AUTOSAR XML (schema 4-2-2)
package /STELLANTIS/EPT/COMSWCs
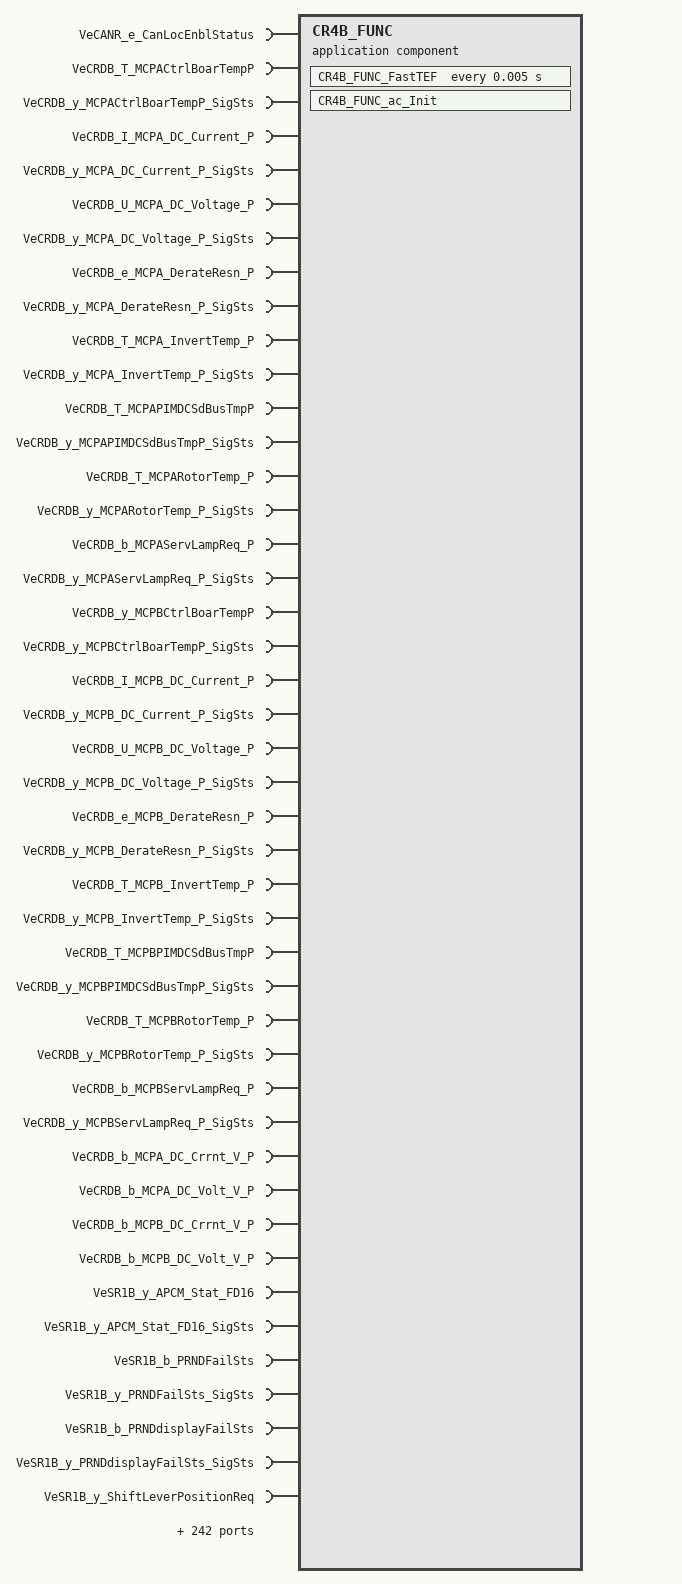
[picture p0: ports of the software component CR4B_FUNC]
  application sw component type CR4B_FUNC
    286 x require port:
      VeCANR_e_CanLocEnblStatus: nonqueued-receiver-com-spec{data-element=VeCANR_e_CanLocEnblStatus, init-value=0}, required-interface=VeCANR_e_CanLocEnblStatus
      VeCRDB_T_MCPACtrlBoarTempP: variation-point={short-label=vpVeCRDB_T_MCPACtrlBoarTempP, sw-syscond=1}, nonqueued-receiver-com-spec{data-element=Value, handle-never-received=true, init-value=0}, required-interface=VeCRDB_T_MCPACtrlBoarTempP
      VeCRDB_y_MCPACtrlBoarTempP_SigSts: variation-point={short-label=vpVeCRDB_y_MCPACtrlBoarTempP_SigSts, sw-syscond=1}, nonqueued-receiver-com-spec{data-element=Value, init-value=0}, required-interface=VeCRDB_y_MCPACtrlBoarTempP_SigSts
      VeCRDB_I_MCPA_DC_Current_P: variation-point={short-label=vpVeCRDB_I_MCPA_DC_Current_P, sw-syscond=1}, nonqueued-receiver-com-spec{data-element=Value, handle-never-received=true, init-value=0}, required-interface=VeCRDB_I_MCPA_DC_Current_P
      VeCRDB_y_MCPA_DC_Current_P_SigSts: variation-point={short-label=vpVeCRDB_y_MCPA_DC_Current_P_SigSts, sw-syscond=1}, nonqueued-receiver-com-spec{data-element=Value, init-value=0}, required-interface=VeCRDB_y_MCPA_DC_Current_P_SigSts
      VeCRDB_U_MCPA_DC_Voltage_P: variation-point={short-label=vpVeCRDB_U_MCPA_DC_Voltage_P, sw-syscond=1}, nonqueued-receiver-com-spec{data-element=Value, handle-never-received=true, init-value=0}, required-interface=VeCRDB_U_MCPA_DC_Voltage_P
      VeCRDB_y_MCPA_DC_Voltage_P_SigSts: variation-point={short-label=vpVeCRDB_y_MCPA_DC_Voltage_P_SigSts, sw-syscond=1}, nonqueued-receiver-com-spec{data-element=Value, init-value=0}, required-interface=VeCRDB_y_MCPA_DC_Voltage_P_SigSts
      VeCRDB_e_MCPA_DerateResn_P: variation-point={short-label=vpVeCRDB_e_MCPA_DerateResn_P, sw-syscond=1}, nonqueued-receiver-com-spec{data-element=Value, handle-never-received=true, init-value=0}, required-interface=VeCRDB_e_MCPA_DerateResn_P
      VeCRDB_y_MCPA_DerateResn_P_SigSts: variation-point={short-label=vpVeCRDB_y_MCPA_DerateResn_P_SigSts, sw-syscond=1}, nonqueued-receiver-com-spec{data-element=Value, init-value=0}, required-interface=VeCRDB_y_MCPA_DerateResn_P_SigSts
      VeCRDB_T_MCPA_InvertTemp_P: variation-point={short-label=vpVeCRDB_T_MCPA_InvertTemp_P, sw-syscond=1}, nonqueued-receiver-com-spec{data-element=Value, handle-never-received=true, init-value=0}, required-interface=VeCRDB_T_MCPA_InvertTemp_P
      VeCRDB_y_MCPA_InvertTemp_P_SigSts: variation-point={short-label=vpVeCRDB_y_MCPA_InvertTemp_P_SigSts, sw-syscond=1}, nonqueued-receiver-com-spec{data-element=Value, init-value=0}, required-interface=VeCRDB_y_MCPA_InvertTemp_P_SigSts
      VeCRDB_T_MCPAPIMDCSdBusTmpP: variation-point={short-label=vpVeCRDB_T_MCPAPIMDCSdBusTmpP, sw-syscond=1}, nonqueued-receiver-com-spec{data-element=Value, handle-never-received=true, init-value=0}, required-interface=VeCRDB_T_MCPAPIMDCSdBusTmpP
      VeCRDB_y_MCPAPIMDCSdBusTmpP_SigSts: variation-point={short-label=vpVeCRDB_y_MCPAPIMDCSdBusTmpP_SigSts, sw-syscond=1}, nonqueued-receiver-com-spec{data-element=Value, init-value=0}, required-interface=VeCRDB_y_MCPAPIMDCSdBusTmpP_SigSts
      VeCRDB_T_MCPARotorTemp_P: variation-point={short-label=vpVeCRDB_T_MCPARotorTemp_P, sw-syscond=1}, nonqueued-receiver-com-spec{data-element=Value, handle-never-received=true, init-value=0}, required-interface=VeCRDB_T_MCPARotorTemp_P
      VeCRDB_y_MCPARotorTemp_P_SigSts: variation-point={short-label=vpVeCRDB_y_MCPARotorTemp_P_SigSts, sw-syscond=1}, nonqueued-receiver-com-spec{data-element=Value, init-value=0}, required-interface=VeCRDB_y_MCPARotorTemp_P_SigSts
      VeCRDB_b_MCPAServLampReq_P: variation-point={short-label=vpVeCRDB_b_MCPAServLampReq_P, sw-syscond=1}, nonqueued-receiver-com-spec{data-element=Value, handle-never-received=true, init-value=0}, required-interface=VeCRDB_b_MCPAServLampReq_P
      VeCRDB_y_MCPAServLampReq_P_SigSts: variation-point={short-label=vpVeCRDB_y_MCPAServLampReq_P_SigSts, sw-syscond=1}, nonqueued-receiver-com-spec{data-element=Value, init-value=0}, required-interface=VeCRDB_y_MCPAServLampReq_P_SigSts
      VeCRDB_y_MCPBCtrlBoarTempP: nonqueued-receiver-com-spec{data-element=Value, handle-never-received=true, init-value=0}, required-interface=VeCRDB_y_MCPBCtrlBoarTempP
      VeCRDB_y_MCPBCtrlBoarTempP_SigSts: nonqueued-receiver-com-spec{data-element=Value, init-value=0}, required-interface=VeCRDB_y_MCPBCtrlBoarTempP_SigSts
      VeCRDB_I_MCPB_DC_Current_P: nonqueued-receiver-com-spec{data-element=Value, handle-never-received=true, init-value=0}, required-interface=VeCRDB_I_MCPB_DC_Current_P
      VeCRDB_y_MCPB_DC_Current_P_SigSts: nonqueued-receiver-com-spec{data-element=Value, init-value=0}, required-interface=VeCRDB_y_MCPB_DC_Current_P_SigSts
      VeCRDB_U_MCPB_DC_Voltage_P: nonqueued-receiver-com-spec{data-element=Value, handle-never-received=true, init-value=0}, required-interface=VeCRDB_U_MCPB_DC_Voltage_P
      VeCRDB_y_MCPB_DC_Voltage_P_SigSts: nonqueued-receiver-com-spec{data-element=Value, init-value=0}, required-interface=VeCRDB_y_MCPB_DC_Voltage_P_SigSts
      VeCRDB_e_MCPB_DerateResn_P: nonqueued-receiver-com-spec{data-element=Value, handle-never-received=true, init-value=0}, required-interface=VeCRDB_e_MCPB_DerateResn_P
      VeCRDB_y_MCPB_DerateResn_P_SigSts: nonqueued-receiver-com-spec{data-element=Value, init-value=0}, required-interface=VeCRDB_y_MCPB_DerateResn_P_SigSts
      VeCRDB_T_MCPB_InvertTemp_P: nonqueued-receiver-com-spec{data-element=Value, handle-never-received=true, init-value=0}, required-interface=VeCRDB_T_MCPB_InvertTemp_P
      VeCRDB_y_MCPB_InvertTemp_P_SigSts: nonqueued-receiver-com-spec{data-element=Value, init-value=0}, required-interface=VeCRDB_y_MCPB_InvertTemp_P_SigSts
      VeCRDB_T_MCPBPIMDCSdBusTmpP: nonqueued-receiver-com-spec{data-element=Value, handle-never-received=true, init-value=0}, required-interface=VeCRDB_T_MCPBPIMDCSdBusTmpP
      VeCRDB_y_MCPBPIMDCSdBusTmpP_SigSts: nonqueued-receiver-com-spec{data-element=Value, init-value=0}, required-interface=VeCRDB_y_MCPBPIMDCSdBusTmpP_SigSts
      VeCRDB_T_MCPBRotorTemp_P: nonqueued-receiver-com-spec{data-element=Value, handle-never-received=true, init-value=0}, required-interface=VeCRDB_T_MCPBRotorTemp_P
      VeCRDB_y_MCPBRotorTemp_P_SigSts: nonqueued-receiver-com-spec{data-element=Value, init-value=0}, required-interface=VeCRDB_y_MCPBRotorTemp_P_SigSts
      VeCRDB_b_MCPBServLampReq_P: nonqueued-receiver-com-spec{data-element=Value, handle-never-received=true, init-value=0}, required-interface=VeCRDB_b_MCPBServLampReq_P
      VeCRDB_y_MCPBServLampReq_P_SigSts: nonqueued-receiver-com-spec{data-element=Value, init-value=0}, required-interface=VeCRDB_y_MCPBServLampReq_P_SigSts
      VeCRDB_b_MCPA_DC_Crrnt_V_P: variation-point={short-label=vpVeCRDB_b_MCPA_DC_Crrnt_V_P, sw-syscond=1}, nonqueued-receiver-com-spec{data-element=Value, init-value=0}, required-interface=VeCRDB_b_MCPA_DC_Crrnt_V_P
      VeCRDB_b_MCPA_DC_Volt_V_P: variation-point={short-label=vpVeCRDB_b_MCPA_DC_Volt_V_P, sw-syscond=1}, nonqueued-receiver-com-spec{data-element=Value, init-value=0}, required-interface=VeCRDB_b_MCPA_DC_Volt_V_P
      VeCRDB_b_MCPB_DC_Crrnt_V_P: nonqueued-receiver-com-spec{data-element=Value, init-value=0}, required-interface=VeCRDB_b_MCPB_DC_Crrnt_V_P
      VeCRDB_b_MCPB_DC_Volt_V_P: nonqueued-receiver-com-spec{data-element=Value, init-value=0}, required-interface=VeCRDB_b_MCPB_DC_Volt_V_P
      VeSR1B_y_APCM_Stat_FD16: nonqueued-receiver-com-spec{data-element=Value, handle-never-received=true, init-value=0}, required-interface=VeSR1B_y_APCM_Stat_FD16
      VeSR1B_y_APCM_Stat_FD16_SigSts: nonqueued-receiver-com-spec{data-element=Value, init-value=0}, required-interface=VeSR1B_y_APCM_Stat_FD16_SigSts
      VeSR1B_b_PRNDFailSts: nonqueued-receiver-com-spec{data-element=Value, handle-never-received=true, init-value=0}, required-interface=VeSR1B_b_PRNDFailSts
      VeSR1B_y_PRNDFailSts_SigSts: nonqueued-receiver-com-spec{data-element=Value, init-value=0}, required-interface=VeSR1B_y_PRNDFailSts_SigSts
      VeSR1B_b_PRNDdisplayFailSts: nonqueued-receiver-com-spec{data-element=Value, handle-never-received=true, init-value=0}, required-interface=VeSR1B_b_PRNDdisplayFailSts
      VeSR1B_y_PRNDdisplayFailSts_SigSts: nonqueued-receiver-com-spec{data-element=Value, init-value=0}, required-interface=VeSR1B_y_PRNDdisplayFailSts_SigSts
      VeSR1B_y_ShiftLeverPositionReq: nonqueued-receiver-com-spec{data-element=Value, handle-never-received=true, init-value=0}, required-interface=VeSR1B_y_ShiftLeverPositionReq
      VeSR1B_y_ShiftLeverPositionReq_SigSts: nonqueued-receiver-com-spec{data-element=Value, init-value=0}, required-interface=VeSR1B_y_ShiftLeverPositionReq_SigSts
      VeCRDB_y_MCPA_6SO_Status_P: variation-point={short-label=vpVeCRDB_y_MCPA_6SO_Status_P, sw-syscond=1}, nonqueued-receiver-com-spec{data-element=Value, handle-never-received=true, init-value=0}, required-interface=VeCRDB_y_MCPA_6SO_Status_P
      VeCRDB_y_MCPA_6SO_Status_P_SigSts: variation-point={short-label=vpVeCRDB_y_MCPA_6SO_Status_P_SigSts, sw-syscond=1}, nonqueued-receiver-com-spec{data-element=Value, init-value=0}, required-interface=VeCRDB_y_MCPA_6SO_Status_P_SigSts
      VeCRDB_y_MCPA_AccelRaw_P: variation-point={short-label=vpVeCRDB_y_MCPA_AccelRaw_P, sw-syscond=1}, nonqueued-receiver-com-spec{data-element=Value, handle-never-received=true, init-value=0}, required-interface=VeCRDB_y_MCPA_AccelRaw_P
      VeCRDB_y_MCPA_AccelRaw_P_SigSts: variation-point={short-label=vpVeCRDB_y_MCPA_AccelRaw_P_SigSts, sw-syscond=1}, nonqueued-receiver-com-spec{data-element=Value, init-value=0}, required-interface=VeCRDB_y_MCPA_AccelRaw_P_SigSts
      VeCRDB_n_MCPA_CpbltySpdDvVolt_P: variation-point={short-label=vpVeCRDB_n_MCPA_CpbltySpdDvVolt_P, sw-syscond=1}, nonqueued-receiver-com-spec{data-element=Value, handle-never-received=true, init-value=0}, required-interface=VeCRDB_n_MCPA_CpbltySpdDvVolt_P
      VeCRDB_y_MCPA_CpbltySpdDvVolt_P_SigSts: variation-point={short-label=vpVeCRDB_y_MCPA_CpbltySpdDvVolt_P_SigSts, sw-syscond=1}, nonqueued-receiver-com-spec{data-element=Value, init-value=0}, required-interface=VeCRDB_y_MCPA_CpbltySpdDvVolt_P_SigSts
      VeCRDB_h_MCPA_DeratingFactor_P: variation-point={short-label=vpVeCRDB_h_MCPA_DeratingFactor_P, sw-syscond=1}, nonqueued-receiver-com-spec{data-element=Value, handle-never-received=true, init-value=0}, required-interface=VeCRDB_h_MCPA_DeratingFactor_P
      VeCRDB_y_MCPA_DeratingFactor_P_SigSts: variation-point={short-label=vpVeCRDB_y_MCPA_DeratingFactor_P_SigSts, sw-syscond=1}, nonqueued-receiver-com-spec{data-element=Value, init-value=0}, required-interface=VeCRDB_y_MCPA_DeratingFactor_P_SigSts
      VeCRDB_y_MCPA_Dschrge_Status_P: variation-point={short-label=vpVeCRDB_y_MCPA_Dschrge_Status_P, sw-syscond=1}, nonqueued-receiver-com-spec{data-element=Value, handle-never-received=true, init-value=0}, required-interface=VeCRDB_y_MCPA_Dschrge_Status_P
      VeCRDB_y_MCPA_Dschrge_Status_P_SigSts: variation-point={short-label=vpVeCRDB_y_MCPA_Dschrge_Status_P_SigSts, sw-syscond=1}, nonqueued-receiver-com-spec{data-element=Value, init-value=0}, required-interface=VeCRDB_y_MCPA_Dschrge_Status_P_SigSts
      VeCRDB_b_MCPA_HV_CnctrOpn_Req_P: variation-point={short-label=vpVeCRDB_b_MCPA_HV_CnctrOpn_Req_P, sw-syscond=1}, nonqueued-receiver-com-spec{data-element=Value, handle-never-received=true, init-value=0}, required-interface=VeCRDB_b_MCPA_HV_CnctrOpn_Req_P
      VeCRDB_y_MCPA_HV_CnctrOpn_Req_P_SigSts: variation-point={short-label=vpVeCRDB_y_MCPA_HV_CnctrOpn_Req_P_SigSts, sw-syscond=1}, nonqueued-receiver-com-spec{data-element=Value, init-value=0}, required-interface=VeCRDB_y_MCPA_HV_CnctrOpn_Req_P_SigSts
      VeCRDB_y_MCPA_InterlockSts_P: variation-point={short-label=vpVeCRDB_y_MCPA_InterlockSts_P, sw-syscond=1}, nonqueued-receiver-com-spec{data-element=Value, handle-never-received=true, init-value=0}, required-interface=VeCRDB_y_MCPA_InterlockSts_P
      VeCRDB_y_MCPA_InterlockSts_P_SigSts: variation-point={short-label=vpVeCRDB_y_MCPA_InterlockSts_P_SigSts, sw-syscond=1}, nonqueued-receiver-com-spec{data-element=Value, init-value=0}, required-interface=VeCRDB_y_MCPA_InterlockSts_P_SigSts
      VeCRDB_y_MCPA_Invrtr_State_P: variation-point={short-label=vpVeCRDB_y_MCPA_Invrtr_State_P, sw-syscond=1}, nonqueued-receiver-com-spec{data-element=Value, handle-never-received=true, init-value=0}, required-interface=VeCRDB_y_MCPA_Invrtr_State_P
      VeCRDB_y_MCPA_Invrtr_State_P_SigSts: variation-point={short-label=vpVeCRDB_y_MCPA_Invrtr_State_P_SigSts, sw-syscond=1}, nonqueued-receiver-com-spec{data-element=Value, init-value=0}, required-interface=VeCRDB_y_MCPA_Invrtr_State_P_SigSts
      VeCRDB_M_MCPA_MaxTorq_P: variation-point={short-label=vpVeCRDB_M_MCPA_MaxTorq_P, sw-syscond=1}, nonqueued-receiver-com-spec{data-element=Value, handle-never-received=true, init-value=0}, required-interface=VeCRDB_M_MCPA_MaxTorq_P
      VeCRDB_y_MCPA_MaxTorq_P_SigSts: variation-point={short-label=vpVeCRDB_y_MCPA_MaxTorq_P_SigSts, sw-syscond=1}, nonqueued-receiver-com-spec{data-element=Value, init-value=0}, required-interface=VeCRDB_y_MCPA_MaxTorq_P_SigSts
      VeCRDB_M_MCPA_MinTorq_P: variation-point={short-label=vpVeCRDB_M_MCPA_MinTorq_P, sw-syscond=1}, nonqueued-receiver-com-spec{data-element=Value, handle-never-received=true, init-value=0}, required-interface=VeCRDB_M_MCPA_MinTorq_P
      VeCRDB_y_MCPA_MinTorq_P_SigSts: variation-point={short-label=vpVeCRDB_y_MCPA_MinTorq_P_SigSts, sw-syscond=1}, nonqueued-receiver-com-spec{data-element=Value, init-value=0}, required-interface=VeCRDB_y_MCPA_MinTorq_P_SigSts
      VeCRDB_M_MCPA_MtrMaxCpbltyTrq_P: variation-point={short-label=vpVeCRDB_M_MCPA_MtrMaxCpbltyTrq_P, sw-syscond=1}, nonqueued-receiver-com-spec{data-element=Value, handle-never-received=true, init-value=0}, required-interface=VeCRDB_M_MCPA_MtrMaxCpbltyTrq_P
      VeCRDB_y_MCPA_MtrMaxCpbltyTrq_P_SigSts: variation-point={short-label=vpVeCRDB_y_MCPA_MtrMaxCpbltyTrq_P_SigSts, sw-syscond=1}, nonqueued-receiver-com-spec{data-element=Value, init-value=0}, required-interface=VeCRDB_y_MCPA_MtrMaxCpbltyTrq_P_SigSts
      VeCRDB_M_MCPA_MtrMinCpbltyTrq_P: variation-point={short-label=vpVeCRDB_M_MCPA_MtrMinCpbltyTrq_P, sw-syscond=1}, nonqueued-receiver-com-spec{data-element=Value, handle-never-received=true, init-value=0}, required-interface=VeCRDB_M_MCPA_MtrMinCpbltyTrq_P
      VeCRDB_y_MCPA_MtrMinCpbltyTrq_P_SigSts: variation-point={short-label=vpVeCRDB_y_MCPA_MtrMinCpbltyTrq_P_SigSts, sw-syscond=1}, nonqueued-receiver-com-spec{data-element=Value, init-value=0}, required-interface=VeCRDB_y_MCPA_MtrMinCpbltyTrq_P_SigSts
      VeCRDB_n_MCPA_RPM_P: variation-point={short-label=vpVeCRDB_n_MCPA_RPM_P, sw-syscond=1}, nonqueued-receiver-com-spec{data-element=Value, handle-never-received=true, init-value=0}, required-interface=VeCRDB_n_MCPA_RPM_P
      VeCRDB_y_MCPA_RPM_P_SigSts: variation-point={short-label=vpVeCRDB_y_MCPA_RPM_P_SigSts, sw-syscond=1}, nonqueued-receiver-com-spec{data-element=Value, init-value=0}, required-interface=VeCRDB_y_MCPA_RPM_P_SigSts
      VeCRDB_b_MCPA_RPM_V_P: variation-point={short-label=vpVeCRDB_b_MCPA_RPM_V_P, sw-syscond=1}, nonqueued-receiver-com-spec{data-element=Value, handle-never-received=true, init-value=0}, required-interface=VeCRDB_b_MCPA_RPM_V_P
      VeCRDB_y_MCPA_RPM_V_P_SigSts: variation-point={short-label=vpVeCRDB_y_MCPA_RPM_V_P_SigSts, sw-syscond=1}, nonqueued-receiver-com-spec{data-element=Value, init-value=0}, required-interface=VeCRDB_y_MCPA_RPM_V_P_SigSts
      VeCRDB_y_MCPA_SPT_Stat_P: variation-point={short-label=vpVeCRDB_y_MCPA_SPT_Stat_P, sw-syscond=1}, nonqueued-receiver-com-spec{data-element=Value, handle-never-received=true, init-value=0}, required-interface=VeCRDB_y_MCPA_SPT_Stat_P
      VeCRDB_y_MCPA_SPT_Stat_P_SigSts: variation-point={short-label=vpVeCRDB_y_MCPA_SPT_Stat_P_SigSts, sw-syscond=1}, nonqueued-receiver-com-spec{data-element=Value, init-value=0}, required-interface=VeCRDB_y_MCPA_SPT_Stat_P_SigSts
      VeCRDB_n_MCPA_Spd_Lim_P: variation-point={short-label=vpVeCRDB_n_MCPA_Spd_Lim_P, sw-syscond=1}, nonqueued-receiver-com-spec{data-element=Value, handle-never-received=true, init-value=0}, required-interface=VeCRDB_n_MCPA_Spd_Lim_P
      VeCRDB_y_MCPA_Spd_Lim_P_SigSts: variation-point={short-label=vpVeCRDB_y_MCPA_Spd_Lim_P_SigSts, sw-syscond=1}, nonqueued-receiver-com-spec{data-element=Value, init-value=0}, required-interface=VeCRDB_y_MCPA_Spd_Lim_P_SigSts
      VeCRDB_T_MCPA_Temp_P: variation-point={short-label=vpVeCRDB_T_MCPA_Temp_P, sw-syscond=1}, nonqueued-receiver-com-spec{data-element=Value, handle-never-received=true, init-value=0}, required-interface=VeCRDB_T_MCPA_Temp_P
      VeCRDB_y_MCPA_Temp_P_SigSts: variation-point={short-label=vpVeCRDB_y_MCPA_Temp_P_SigSts, sw-syscond=1}, nonqueued-receiver-com-spec{data-element=Value, init-value=0}, required-interface=VeCRDB_y_MCPA_Temp_P_SigSts
      VeCRDB_M_MCPA_TorqAchved_AEMD_P: variation-point={short-label=vpVeCRDB_M_MCPA_TorqAchved_AEMD_P, sw-syscond=1}, nonqueued-receiver-com-spec{data-element=Value, handle-never-received=true, init-value=0}, required-interface=VeCRDB_M_MCPA_TorqAchved_AEMD_P
      VeCRDB_y_MCPA_TorqAchved_AEMD_P_SigSts: variation-point={short-label=vpVeCRDB_y_MCPA_TorqAchved_AEMD_P_SigSts, sw-syscond=1}, nonqueued-receiver-com-spec{data-element=Value, init-value=0}, required-interface=VeCRDB_y_MCPA_TorqAchved_AEMD_P_SigSts
      VeCRDB_M_MCPA_Torque_Achieved_P: variation-point={short-label=vpVeCRDB_M_MCPA_Torque_Achieved_P, sw-syscond=1}, nonqueued-receiver-com-spec{data-element=Value, handle-never-received=true, init-value=0}, required-interface=VeCRDB_M_MCPA_Torque_Achieved_P
      VeCRDB_y_MCPA_Torque_Achieved_P_SigSts: variation-point={short-label=vpVeCRDB_y_MCPA_Torque_Achieved_P_SigSts, sw-syscond=1}, nonqueued-receiver-com-spec{data-element=Value, init-value=0}, required-interface=VeCRDB_y_MCPA_Torque_Achieved_P_SigSts
      VeCRDB_b_MCPA_Torque_Achved_V_P: variation-point={short-label=vpVeCRDB_b_MCPA_Torque_Achved_V_P, sw-syscond=1}, nonqueued-receiver-com-spec{data-element=Value, handle-never-received=true, init-value=0}, required-interface=VeCRDB_b_MCPA_Torque_Achved_V_P
      VeCRDB_y_MCPA_Torque_Achved_V_P_SigSts: variation-point={short-label=vpVeCRDB_y_MCPA_Torque_Achved_V_P_SigSts, sw-syscond=1}, nonqueued-receiver-com-spec{data-element=Value, init-value=0}, required-interface=VeCRDB_y_MCPA_Torque_Achved_V_P_SigSts
      VeCRDB_y_MCPB_6SO_Status_P: nonqueued-receiver-com-spec{data-element=Value, handle-never-received=true, init-value=0}, required-interface=VeCRDB_y_MCPB_6SO_Status_P
      VeCRDB_y_MCPB_6SO_Status_P_SigSts: nonqueued-receiver-com-spec{data-element=Value, init-value=0}, required-interface=VeCRDB_y_MCPB_6SO_Status_P_SigSts
      VeCRDB_y_MCPB_AccelRaw_P: nonqueued-receiver-com-spec{data-element=Value, handle-never-received=true, init-value=0}, required-interface=VeCRDB_y_MCPB_AccelRaw_P
      VeCRDB_y_MCPB_AccelRaw_P_SigSts: nonqueued-receiver-com-spec{data-element=Value, init-value=0}, required-interface=VeCRDB_y_MCPB_AccelRaw_P_SigSts
      VeCRDB_U_MCPB_CpbltySpdDvVolt_P: nonqueued-receiver-com-spec{data-element=Value, handle-never-received=true, init-value=0}, required-interface=VeCRDB_U_MCPB_CpbltySpdDvVolt_P
      VeCRDB_y_MCPB_CpbltySpdDvVolt_P_SigSts: nonqueued-receiver-com-spec{data-element=Value, init-value=0}, required-interface=VeCRDB_y_MCPB_CpbltySpdDvVolt_P_SigSts
      VeCRDB_h_MCPB_DeratingFactor_P: nonqueued-receiver-com-spec{data-element=Value, handle-never-received=true, init-value=0}, required-interface=VeCRDB_h_MCPB_DeratingFactor_P
      VeCRDB_y_MCPB_DeratingFactor_P_SigSts: nonqueued-receiver-com-spec{data-element=Value, init-value=0}, required-interface=VeCRDB_y_MCPB_DeratingFactor_P_SigSts
      VeCRDB_y_MCPB_Dschrge_Status_P: nonqueued-receiver-com-spec{data-element=Value, handle-never-received=true, init-value=0}, required-interface=VeCRDB_y_MCPB_Dschrge_Status_P
      VeCRDB_y_MCPB_Dschrge_Status_P_SigSts: nonqueued-receiver-com-spec{data-element=Value, init-value=0}, required-interface=VeCRDB_y_MCPB_Dschrge_Status_P_SigSts
      VeCRDB_b_MCPB_HV_CnctrOpn_Req_P: nonqueued-receiver-com-spec{data-element=Value, handle-never-received=true, init-value=0}, required-interface=VeCRDB_b_MCPB_HV_CnctrOpn_Req_P
      VeCRDB_y_MCPB_HV_CnctrOpn_Req_P_SigSts: nonqueued-receiver-com-spec{data-element=Value, init-value=0}, required-interface=VeCRDB_y_MCPB_HV_CnctrOpn_Req_P_SigSts
      VeCRDB_y_MCPB_InterlockSts_P: nonqueued-receiver-com-spec{data-element=Value, handle-never-received=true, init-value=0}, required-interface=VeCRDB_y_MCPB_InterlockSts_P
      VeCRDB_y_MCPB_InterlockSts_P_SigSts: nonqueued-receiver-com-spec{data-element=Value, init-value=0}, required-interface=VeCRDB_y_MCPB_InterlockSts_P_SigSts
      VeCRDB_y_MCPB_Invrtr_State_P: nonqueued-receiver-com-spec{data-element=Value, handle-never-received=true, init-value=0}, required-interface=VeCRDB_y_MCPB_Invrtr_State_P
      VeCRDB_y_MCPB_Invrtr_State_P_SigSts: nonqueued-receiver-com-spec{data-element=Value, init-value=0}, required-interface=VeCRDB_y_MCPB_Invrtr_State_P_SigSts
      VeCRDB_M_MCPB_MaxTorq_P: nonqueued-receiver-com-spec{data-element=Value, handle-never-received=true, init-value=0}, required-interface=VeCRDB_M_MCPB_MaxTorq_P
      VeCRDB_y_MCPB_MaxTorq_P_SigSts: nonqueued-receiver-com-spec{data-element=Value, init-value=0}, required-interface=VeCRDB_y_MCPB_MaxTorq_P_SigSts
      VeCRDB_M_MCPB_MinTorq_P: nonqueued-receiver-com-spec{data-element=Value, handle-never-received=true, init-value=0}, required-interface=VeCRDB_M_MCPB_MinTorq_P
      VeCRDB_y_MCPB_MinTorq_P_SigSts: nonqueued-receiver-com-spec{data-element=Value, init-value=0}, required-interface=VeCRDB_y_MCPB_MinTorq_P_SigSts
      VeCRDB_M_MCPB_MtrMaxCpbltyTrq_P: nonqueued-receiver-com-spec{data-element=Value, handle-never-received=true, init-value=0}, required-interface=VeCRDB_M_MCPB_MtrMaxCpbltyTrq_P
      VeCRDB_y_MCPB_MtrMaxCpbltyTrq_P_SigSts: nonqueued-receiver-com-spec{data-element=Value, init-value=0}, required-interface=VeCRDB_y_MCPB_MtrMaxCpbltyTrq_P_SigSts
      VeCRDB_M_MCPB_MtrMinCpbltyTrq_P: nonqueued-receiver-com-spec{data-element=Value, handle-never-received=true, init-value=0}, required-interface=VeCRDB_M_MCPB_MtrMinCpbltyTrq_P
      VeCRDB_y_MCPB_MtrMinCpbltyTrq_P_SigSts: nonqueued-receiver-com-spec{data-element=Value, init-value=0}, required-interface=VeCRDB_y_MCPB_MtrMinCpbltyTrq_P_SigSts
      VeCRDB_n_MCPB_RPM_P: nonqueued-receiver-com-spec{data-element=Value, handle-never-received=true, init-value=0}, required-interface=VeCRDB_n_MCPB_RPM_P
      VeCRDB_y_MCPB_RPM_P_SigSts: nonqueued-receiver-com-spec{data-element=Value, init-value=0}, required-interface=VeCRDB_y_MCPB_RPM_P_SigSts
      VeCRDB_y_MCPB_SPT_Stat_P: nonqueued-receiver-com-spec{data-element=Value, handle-never-received=true, init-value=0}, required-interface=VeCRDB_y_MCPB_SPT_Stat_P
      VeCRDB_y_MCPB_SPT_Stat_P_SigSts: nonqueued-receiver-com-spec{data-element=Value, init-value=0}, required-interface=VeCRDB_y_MCPB_SPT_Stat_P_SigSts
      VeCRDB_n_MCPB_Spd_Lim_P: nonqueued-receiver-com-spec{data-element=Value, handle-never-received=true, init-value=0}, required-interface=VeCRDB_n_MCPB_Spd_Lim_P
      VeCRDB_y_MCPB_Spd_Lim_P_SigSts: nonqueued-receiver-com-spec{data-element=Value, init-value=0}, required-interface=VeCRDB_y_MCPB_Spd_Lim_P_SigSts
      VeCRDB_y_MCPB_Temp_P: nonqueued-receiver-com-spec{data-element=Value, handle-never-received=true, init-value=0}, required-interface=VeCRDB_y_MCPB_Temp_P
      VeCRDB_y_MCPB_Temp_P_SigSts: nonqueued-receiver-com-spec{data-element=Value, init-value=0}, required-interface=VeCRDB_y_MCPB_Temp_P_SigSts
      VeCRDB_M_MCPB_TorqAchved_AEMD_P: nonqueued-receiver-com-spec{data-element=Value, handle-never-received=true, init-value=0}, required-interface=VeCRDB_M_MCPB_TorqAchved_AEMD_P
      VeCRDB_y_MCPB_TorqAchved_AEMD_P_SigSts: nonqueued-receiver-com-spec{data-element=Value, init-value=0}, required-interface=VeCRDB_y_MCPB_TorqAchved_AEMD_P_SigSts
      VeCRDB_M_MCPB_Torque_Achieved_P: nonqueued-receiver-com-spec{data-element=Value, handle-never-received=true, init-value=0}, required-interface=VeCRDB_M_MCPB_Torque_Achieved_P
      VeCRDB_y_MCPB_Torque_Achieved_P_SigSts: nonqueued-receiver-com-spec{data-element=Value, init-value=0}, required-interface=VeCRDB_y_MCPB_Torque_Achieved_P_SigSts
      VeCRDB_y_MPR_PosSensor_P: nonqueued-receiver-com-spec{data-element=Value, handle-never-received=true, init-value=0}, required-interface=VeCRDB_y_MPR_PosSensor_P
      VeCRDB_y_MPR_PosSensor_P_SigSts: nonqueued-receiver-com-spec{data-element=Value, init-value=0}, required-interface=VeCRDB_y_MPR_PosSensor_P_SigSts
      VeCRDB_y_PlockFailSts_P: nonqueued-receiver-com-spec{data-element=Value, handle-never-received=true, init-value=0}, required-interface=VeCRDB_y_PlockFailSts_P
      VeCRDB_y_PlockFailSts_P_SigSts: nonqueued-receiver-com-spec{data-element=Value, init-value=0}, required-interface=VeCRDB_y_PlockFailSts_P_SigSts
      VeCRDB_y_Plock_MotorPosSts_P: nonqueued-receiver-com-spec{data-element=Value, handle-never-received=true, init-value=0}, required-interface=VeCRDB_y_Plock_MotorPosSts_P
      VeCRDB_y_Plock_MotorPosSts_P_SigSts: nonqueued-receiver-com-spec{data-element=Value, init-value=0}, required-interface=VeCRDB_y_Plock_MotorPosSts_P_SigSts
      VeCRDB_y_Plock_PosSensor_P: nonqueued-receiver-com-spec{data-element=Value, handle-never-received=true, init-value=0}, required-interface=VeCRDB_y_Plock_PosSensor_P
      VeCRDB_y_Plock_PosSensor_P_SigSts: nonqueued-receiver-com-spec{data-element=Value, init-value=0}, required-interface=VeCRDB_y_Plock_PosSensor_P_SigSts
      VeCRDB_y_Plock_fdbk_sts_P: nonqueued-receiver-com-spec{data-element=Value, handle-never-received=true, init-value=0}, required-interface=VeCRDB_y_Plock_fdbk_sts_P
      VeCRDB_y_Plock_fdbk_sts_P_SigSts: nonqueued-receiver-com-spec{data-element=Value, init-value=0}, required-interface=VeCRDB_y_Plock_fdbk_sts_P_SigSts
      VeSR1B_b_MCPA_AccelRawV_P_FD16: variation-point={short-label=vpVeSR1B_b_MCPA_AccelRawV_P_FD16, sw-syscond=1}, nonqueued-receiver-com-spec{data-element=Value, init-value=0}, required-interface=VeSR1B_b_MCPA_AccelRawV_P_FD16
      VeSR1B_y_MCPA_MtrIndex_P_FD16: variation-point={short-label=vpVeSR1B_y_MCPA_MtrIndex_P_FD16, sw-syscond=1}, nonqueued-receiver-com-spec{data-element=Value, init-value=0}, required-interface=VeSR1B_y_MCPA_MtrIndex_P_FD16
      VeSR1B_b_MCPA_RPM_V_P_FD16: variation-point={short-label=vpVeSR1B_b_MCPA_RPM_V_P_FD16, sw-syscond=1}, nonqueued-receiver-com-spec{data-element=Value, init-value=0}, required-interface=VeSR1B_b_MCPA_RPM_V_P_FD16
      VeSR1B_b_MCPA_TrqAchvd_AEMD_V_P_FD16: variation-point={short-label=vpVeSR1B_b_MCPA_TrqAchvd_AEMD_V_P_FD16, sw-syscond=1}, nonqueued-receiver-com-spec{data-element=Value, init-value=0}, required-interface=VeSR1B_b_MCPA_TrqAchvd_AEMD_V_P_FD16
      VeSR1B_b_MCPA_Torque_Achved_V_P_FD16: variation-point={short-label=vpVeSR1B_b_MCPA_Torque_Achved_V_P_FD16, sw-syscond=1}, nonqueued-receiver-com-spec{data-element=Value, init-value=0}, required-interface=VeSR1B_b_MCPA_Torque_Achved_V_P_FD16
      VeSR1B_b_MCPB_AccelRawV_P_FD16: nonqueued-receiver-com-spec{data-element=Value, init-value=0}, required-interface=VeSR1B_b_MCPB_AccelRawV_P_FD16
      VeSR1B_y_MCPB_MtrIndex_P_FD16: nonqueued-receiver-com-spec{data-element=Value, init-value=0}, required-interface=VeSR1B_y_MCPB_MtrIndex_P_FD16
      VeSR1B_b_MCPB_RPM_V_P_FD16: nonqueued-receiver-com-spec{data-element=Value, init-value=0}, required-interface=VeSR1B_b_MCPB_RPM_V_P_FD16
      VeSR1B_b_MCPB_TrqAchvd_AEMD_V_P_FD16: nonqueued-receiver-com-spec{data-element=Value, init-value=0}, required-interface=VeSR1B_b_MCPB_TrqAchvd_AEMD_V_P_FD16
      VeSR1B_b_MCPB_Torque_Achved_V_P_FD16: nonqueued-receiver-com-spec{data-element=Value, init-value=0}, required-interface=VeSR1B_b_MCPB_Torque_Achved_V_P_FD16
      FsftPLTR_b_Scndry_AutoPosCorrMd: client-com-spec=FsftPLTR_b_Scndry_AutoPosCorrMd, required-interface=FsftPLTR_b_Scndry_AutoPosCorrMd
      PokePLTR_e_Scndry_AutoPosCorrMd: client-com-spec=PokePLTR_e_Scndry_AutoPosCorrMd, required-interface=PokePLTR_e_Scndry_AutoPosCorrMd
      FsftPLTR_b_Scndry_ShiftSnsFA: client-com-spec=FsftPLTR_b_Scndry_ShiftSnsFA, required-interface=FsftPLTR_b_Scndry_ShiftSnsFA
      PokePLTR_b_Scndry_ShiftSnsFA: client-com-spec=PokePLTR_b_Scndry_ShiftSnsFA, required-interface=PokePLTR_b_Scndry_ShiftSnsFA
      FsftPLTR_b_Scndry_ShifterDispFA: client-com-spec=FsftPLTR_b_Scndry_ShifterDispFA, required-interface=FsftPLTR_b_Scndry_ShifterDispFA
      PokePLTR_b_Scndry_ShifterDispFA: client-com-spec=PokePLTR_b_Scndry_ShifterDispFA, required-interface=PokePLTR_b_Scndry_ShifterDispFA
      FsftPLTR_b_Scndry_TransShiftPstn: client-com-spec=FsftPLTR_b_Scndry_TransShiftPstn, required-interface=FsftPLTR_b_Scndry_TransShiftPstn
      PokePLTR_e_Scndry_TransShiftPstn: client-com-spec=PokePLTR_e_Scndry_TransShiftPstn, required-interface=PokePLTR_e_Scndry_TransShiftPstn
      PokeINVR_e_MtrA_6SOEnbl: variation-point={short-label=vpPokeINVR_e_MtrA_6SOEnbl, sw-syscond=1}, client-com-spec=PokeINVR_e_MtrA_6SOEnbl, required-interface=PokeINVR_e_MtrA_6SOEnbl
      TmotINVR_b_MtrA_6SOEnbl: variation-point={short-label=vpTmotINVR_b_MtrA_6SOEnbl, sw-syscond=1}, client-com-spec=TmotINVR_b_MtrA_6SOEnbl, required-interface=TmotINVR_b_MtrA_6SOEnbl
      FsftMSPR_dn_MtrA_AccelRaw: variation-point={short-label=vpFsftMSPR_dn_MtrA_AccelRaw, sw-syscond=1}, client-com-spec=FsftMSPR_dn_MtrA_AccelRaw, required-interface=FsftMSPR_dn_MtrA_AccelRaw
      PokeMSPR_dn_MtrA_AccelRaw: variation-point={short-label=vpPokeMSPR_dn_MtrA_AccelRaw, sw-syscond=1}, client-com-spec=PokeMSPR_dn_MtrA_AccelRaw, required-interface=PokeMSPR_dn_MtrA_AccelRaw
      TmotMSPR_b_MtrA_AccelRaw: variation-point={short-label=vpTmotMSPR_b_MtrA_AccelRaw, sw-syscond=1}, client-com-spec=TmotMSPR_b_MtrA_AccelRaw, required-interface=TmotMSPR_b_MtrA_AccelRaw
      FsftMTIR_n_MtrACapabilitySpd: variation-point={short-label=vpFsftMTIR_n_MtrACapabilitySpd, sw-syscond=1}, client-com-spec=FsftMTIR_n_MtrACapabilitySpd, required-interface=FsftMTIR_n_MtrACapabilitySpd
      PokeMTIR_n_MtrACapabilitySpd: variation-point={short-label=vpPokeMTIR_n_MtrACapabilitySpd, sw-syscond=1}, client-com-spec=PokeMTIR_n_MtrACapabilitySpd, required-interface=PokeMTIR_n_MtrACapabilitySpd
      FsftMTIR_k_MtrADeratingFactor: variation-point={short-label=vpFsftMTIR_k_MtrADeratingFactor, sw-syscond=1}, client-com-spec=FsftMTIR_k_MtrADeratingFactor, required-interface=FsftMTIR_k_MtrADeratingFactor
      PokeMTIR_k_MtrADeratingFactor: variation-point={short-label=vpPokeMTIR_k_MtrADeratingFactor, sw-syscond=1}, client-com-spec=PokeMTIR_k_MtrADeratingFactor, required-interface=PokeMTIR_k_MtrADeratingFactor
      FsftINVR_e_MtrA_Dschrge_Stat: variation-point={short-label=vpFsftINVR_e_MtrA_Dschrge_Stat, sw-syscond=1}, client-com-spec=FsftINVR_e_MtrA_Dschrge_Stat, required-interface=FsftINVR_e_MtrA_Dschrge_Stat
      PokeINVR_e_MtrA_Dschrge_Stat: variation-point={short-label=vpPokeINVR_e_MtrA_Dschrge_Stat, sw-syscond=1}, client-com-spec=PokeINVR_e_MtrA_Dschrge_Stat, required-interface=PokeINVR_e_MtrA_Dschrge_Stat
      FsftINVR_b_MtrAFlt_HV_CntctrOpnRq: variation-point={short-label=vpFsftINVR_b_MtrAFlt_HV_CntctrOpnRq, sw-syscond=1}, client-com-spec=FsftINVR_b_MtrAFlt_HV_CntctrOpnRq, required-interface=FsftINVR_b_MtrAFlt_HV_CntctrOpnRq
      PokeINVR_b_MtrAFlt_HV_CntctrOpnRq: variation-point={short-label=vpPokeINVR_b_MtrAFlt_HV_CntctrOpnRq, sw-syscond=1}, client-com-spec=PokeINVR_b_MtrAFlt_HV_CntctrOpnRq, required-interface=PokeINVR_b_MtrAFlt_HV_CntctrOpnRq
      FsftINVR_b_MCPA_HVILSts: variation-point={short-label=vpFsftINVR_b_MCPA_HVILSts, sw-syscond=1}, client-com-spec=FsftINVR_b_MCPA_HVILSts, required-interface=FsftINVR_b_MCPA_HVILSts
      PokeINVR_e_MCPA_HVILSts: variation-point={short-label=vpPokeINVR_e_MCPA_HVILSts, sw-syscond=1}, client-com-spec=PokeINVR_e_MCPA_HVILSts, required-interface=PokeINVR_e_MCPA_HVILSts
      FsftINVR_e_MtrA_InvrtrSt: variation-point={short-label=vpFsftINVR_e_MtrA_InvrtrSt, sw-syscond=1}, client-com-spec=FsftINVR_e_MtrA_InvrtrSt, required-interface=FsftINVR_e_MtrA_InvrtrSt
      PokeINVR_e_MtrA_InvrtrSt: variation-point={short-label=vpPokeINVR_e_MtrA_InvrtrSt, sw-syscond=1}, client-com-spec=PokeINVR_e_MtrA_InvrtrSt, required-interface=PokeINVR_e_MtrA_InvrtrSt
      TmotINVR_b_MtrA_InvrtrSt: variation-point={short-label=vpTmotINVR_b_MtrA_InvrtrSt, sw-syscond=1}, client-com-spec=TmotINVR_b_MtrA_InvrtrSt, required-interface=TmotINVR_b_MtrA_InvrtrSt
      FsftMTIR_M_MtrA_MaxTorq: variation-point={short-label=vpFsftMTIR_M_MtrA_MaxTorq, sw-syscond=1}, client-com-spec=FsftMTIR_M_MtrA_MaxTorq, required-interface=FsftMTIR_M_MtrA_MaxTorq
      PokeMTIR_M_MtrA_MaxTorq: variation-point={short-label=vpPokeMTIR_M_MtrA_MaxTorq, sw-syscond=1}, client-com-spec=PokeMTIR_M_MtrA_MaxTorq, required-interface=PokeMTIR_M_MtrA_MaxTorq
      FsftMTIR_M_MtrA_MinTorq: variation-point={short-label=vpFsftMTIR_M_MtrA_MinTorq, sw-syscond=1}, client-com-spec=FsftMTIR_M_MtrA_MinTorq, required-interface=FsftMTIR_M_MtrA_MinTorq
      PokeMTIR_M_MtrA_MinTorq: variation-point={short-label=vpPokeMTIR_M_MtrA_MinTorq, sw-syscond=1}, client-com-spec=PokeMTIR_M_MtrA_MinTorq, required-interface=PokeMTIR_M_MtrA_MinTorq
      FsftMTIR_M_MtrACapabilityMax: variation-point={short-label=vpFsftMTIR_M_MtrACapabilityMax, sw-syscond=1}, client-com-spec=FsftMTIR_M_MtrACapabilityMax, required-interface=FsftMTIR_M_MtrACapabilityMax
      PokeMTIR_M_MtrACapabilityMax: variation-point={short-label=vpPokeMTIR_M_MtrACapabilityMax, sw-syscond=1}, client-com-spec=PokeMTIR_M_MtrACapabilityMax, required-interface=PokeMTIR_M_MtrACapabilityMax
      FsftMTIR_M_MtrACapabilityMin: variation-point={short-label=vpFsftMTIR_M_MtrACapabilityMin, sw-syscond=1}, client-com-spec=FsftMTIR_M_MtrACapabilityMin, required-interface=FsftMTIR_M_MtrACapabilityMin
      PokeMTIR_M_MtrACapabilityMin: variation-point={short-label=vpPokeMTIR_M_MtrACapabilityMin, sw-syscond=1}, client-com-spec=PokeMTIR_M_MtrACapabilityMin, required-interface=PokeMTIR_M_MtrACapabilityMin
      FsftMSPR_n_MtrA_SpdRaw: variation-point={short-label=vpFsftMSPR_n_MtrA_SpdRaw, sw-syscond=1}, client-com-spec=FsftMSPR_n_MtrA_SpdRaw, required-interface=FsftMSPR_n_MtrA_SpdRaw
      PokeMSPR_n_MtrA_SpdRaw: variation-point={short-label=vpPokeMSPR_n_MtrA_SpdRaw, sw-syscond=1}, client-com-spec=PokeMSPR_n_MtrA_SpdRaw, required-interface=PokeMSPR_n_MtrA_SpdRaw
      TmotMSPR_b_MtrA_SpdRaw: variation-point={short-label=vpTmotMSPR_b_MtrA_SpdRaw, sw-syscond=1}, client-com-spec=TmotMSPR_b_MtrA_SpdRaw, required-interface=TmotMSPR_b_MtrA_SpdRaw
      PokeINVR_b_MtrA_SpdRawFA: variation-point={short-label=vpPokeINVR_b_MtrA_SpdRawFA, sw-syscond=1}, client-com-spec=PokeINVR_b_MtrA_SpdRawFA, required-interface=PokeINVR_b_MtrA_SpdRawFA
      FsftINVR_e_MCPA_SPT_State: variation-point={short-label=vpFsftINVR_e_MCPA_SPT_State, sw-syscond=1}, client-com-spec=FsftINVR_e_MCPA_SPT_State, required-interface=FsftINVR_e_MCPA_SPT_State
      PokeINVR_e_MCPA_SPT_State: variation-point={short-label=vpPokeINVR_e_MCPA_SPT_State, sw-syscond=1}, client-com-spec=PokeINVR_e_MCPA_SPT_State, required-interface=PokeINVR_e_MCPA_SPT_State
      TmotINVR_b_MCPA_SPT_State: variation-point={short-label=vpTmotINVR_b_MCPA_SPT_State, sw-syscond=1}, client-com-spec=TmotINVR_b_MCPA_SPT_State, required-interface=TmotINVR_b_MCPA_SPT_State
      FsftMSPR_n_MaxP1SpdLmt: variation-point={short-label=vpFsftMSPR_n_MaxP1SpdLmt, sw-syscond=1}, client-com-spec=FsftMSPR_n_MaxP1SpdLmt, required-interface=FsftMSPR_n_MaxP1SpdLmt
      PokeMSPR_n_MaxP1SpdLmt: variation-point={short-label=vpPokeMSPR_n_MaxP1SpdLmt, sw-syscond=1}, client-com-spec=PokeMSPR_n_MaxP1SpdLmt, required-interface=PokeMSPR_n_MaxP1SpdLmt
      TmotMSPR_n_MaxP1SpdLmt: variation-point={short-label=vpTmotMSPR_n_MaxP1SpdLmt, sw-syscond=1}, client-com-spec=TmotMSPR_n_MaxP1SpdLmt, required-interface=TmotMSPR_n_MaxP1SpdLmt
      FsftINVR_T_MtrA_Temp: variation-point={short-label=vpFsftINVR_T_MtrA_Temp, sw-syscond=1}, client-com-spec=FsftINVR_T_MtrA_Temp, required-interface=FsftINVR_T_MtrA_Temp
      PokeINVR_T_MtrA_Temp: variation-point={short-label=vpPokeINVR_T_MtrA_Temp, sw-syscond=1}, client-com-spec=PokeINVR_T_MtrA_Temp, required-interface=PokeINVR_T_MtrA_Temp
      TmotINVR_b_MtrA_Temp: variation-point={short-label=vpTmotINVR_b_MtrA_Temp, sw-syscond=1}, client-com-spec=TmotINVR_b_MtrA_Temp, required-interface=TmotINVR_b_MtrA_Temp
      FsftMTIR_M_MtrA_TorqAchieved_AEMD: variation-point={short-label=vpFsftMTIR_M_MtrA_TorqAchieved_AEMD, sw-syscond=1}, client-com-spec=FsftMTIR_M_MtrA_TorqAchieved_AEMD, required-interface=FsftMTIR_M_MtrA_TorqAchieved_AEMD
      PokeMTIR_M_MtrA_TorqAchieved_AEMD: variation-point={short-label=vpPokeMTIR_M_MtrA_TorqAchieved_AEMD, sw-syscond=1}, client-com-spec=PokeMTIR_M_MtrA_TorqAchieved_AEMD, required-interface=PokeMTIR_M_MtrA_TorqAchieved_AEMD
      TmotMTIR_b_MtrA_TorqAchieved_AEMD: variation-point={short-label=vpTmotMTIR_b_MtrA_TorqAchieved_AEMD, sw-syscond=1}, client-com-spec=TmotMTIR_b_MtrA_TorqAchieved_AEMD, required-interface=TmotMTIR_b_MtrA_TorqAchieved_AEMD
      FsftMTIR_M_MtrA_TorqAchieved: variation-point={short-label=vpFsftMTIR_M_MtrA_TorqAchieved, sw-syscond=1}, client-com-spec=FsftMTIR_M_MtrA_TorqAchieved, required-interface=FsftMTIR_M_MtrA_TorqAchieved
      PokeMTIR_M_MtrA_TorqAchieved: variation-point={short-label=vpPokeMTIR_M_MtrA_TorqAchieved, sw-syscond=1}, client-com-spec=PokeMTIR_M_MtrA_TorqAchieved, required-interface=PokeMTIR_M_MtrA_TorqAchieved
      PokeINVR_b_MtrA_TorqAchievedFA: variation-point={short-label=vpPokeINVR_b_MtrA_TorqAchievedFA, sw-syscond=1}, client-com-spec=PokeINVR_b_MtrA_TorqAchievedFA, required-interface=PokeINVR_b_MtrA_TorqAchievedFA
      FsftINVR_T_MtrA_CtrlBoard_Temp: variation-point={short-label=vpFsftINVR_T_MtrA_CtrlBoard_Temp, sw-syscond=1}, client-com-spec=FsftINVR_T_MtrA_CtrlBoard_Temp, required-interface=FsftINVR_T_MtrA_CtrlBoard_Temp
      PokeINVR_T_MtrA_CtrlBoard_Temp: variation-point={short-label=vpPokeINVR_T_MtrA_CtrlBoard_Temp, sw-syscond=1}, client-com-spec=PokeINVR_T_MtrA_CtrlBoard_Temp, required-interface=PokeINVR_T_MtrA_CtrlBoard_Temp
      TmotINVR_b_MtrA_CtrlBoard_Temp: variation-point={short-label=vpTmotINVR_b_MtrA_CtrlBoard_Temp, sw-syscond=1}, client-com-spec=TmotINVR_b_MtrA_CtrlBoard_Temp, required-interface=TmotINVR_b_MtrA_CtrlBoard_Temp
      FsftINVR_I_MtrA_DC_Crnt: variation-point={short-label=vpFsftINVR_I_MtrA_DC_Crnt, sw-syscond=1}, client-com-spec=FsftINVR_I_MtrA_DC_Crnt, required-interface=FsftINVR_I_MtrA_DC_Crnt
      PokeINVR_I_MtrA_DC_Crnt: variation-point={short-label=vpPokeINVR_I_MtrA_DC_Crnt, sw-syscond=1}, client-com-spec=PokeINVR_I_MtrA_DC_Crnt, required-interface=PokeINVR_I_MtrA_DC_Crnt
      TmotINVR_b_MtrA_DC_Crnt: variation-point={short-label=vpTmotINVR_b_MtrA_DC_Crnt, sw-syscond=1}, client-com-spec=TmotINVR_b_MtrA_DC_Crnt, required-interface=TmotINVR_b_MtrA_DC_Crnt
      FsftINVR_U_MtrA_DC_Volt: variation-point={short-label=vpFsftINVR_U_MtrA_DC_Volt, sw-syscond=1}, client-com-spec=FsftINVR_U_MtrA_DC_Volt, required-interface=FsftINVR_U_MtrA_DC_Volt
      PokeINVR_U_MtrA_DC_Volt: variation-point={short-label=vpPokeINVR_U_MtrA_DC_Volt, sw-syscond=1}, client-com-spec=PokeINVR_U_MtrA_DC_Volt, required-interface=PokeINVR_U_MtrA_DC_Volt
      TmotINVR_b_MtrA_DC_Volt: variation-point={short-label=vpTmotINVR_b_MtrA_DC_Volt, sw-syscond=1}, client-com-spec=TmotINVR_b_MtrA_DC_Volt, required-interface=TmotINVR_b_MtrA_DC_Volt
      PokeINVR_e_MtrA_DrtRsn: variation-point={short-label=vpPokeINVR_e_MtrA_DrtRsn, sw-syscond=1}, client-com-spec=PokeINVR_e_MtrA_DrtRsn, required-interface=PokeINVR_e_MtrA_DrtRsn
      FsftINVR_T_MtrA_InvrtrTemp: variation-point={short-label=vpFsftINVR_T_MtrA_InvrtrTemp, sw-syscond=1}, client-com-spec=FsftINVR_T_MtrA_InvrtrTemp, required-interface=FsftINVR_T_MtrA_InvrtrTemp
      PokeINVR_T_MtrA_InvrtrTemp: variation-point={short-label=vpPokeINVR_T_MtrA_InvrtrTemp, sw-syscond=1}, client-com-spec=PokeINVR_T_MtrA_InvrtrTemp, required-interface=PokeINVR_T_MtrA_InvrtrTemp
      TmotINVR_b_MtrA_InvrtrTemp: variation-point={short-label=vpTmotINVR_b_MtrA_InvrtrTemp, sw-syscond=1}, client-com-spec=TmotINVR_b_MtrA_InvrtrTemp, required-interface=TmotINVR_b_MtrA_InvrtrTemp
      FsftINVR_T_GPIMDCBusBarTemp: variation-point={short-label=vpFsftINVR_T_GPIMDCBusBarTemp, sw-syscond=1}, client-com-spec=FsftINVR_T_GPIMDCBusBarTemp, required-interface=FsftINVR_T_GPIMDCBusBarTemp
      PokeINVR_T_GPIMDCBusBarTemp: variation-point={short-label=vpPokeINVR_T_GPIMDCBusBarTemp, sw-syscond=1}, client-com-spec=PokeINVR_T_GPIMDCBusBarTemp, required-interface=PokeINVR_T_GPIMDCBusBarTemp
      FsftINVR_T_MtrA_RotrTemp: variation-point={short-label=vpFsftINVR_T_MtrA_RotrTemp, sw-syscond=1}, client-com-spec=FsftINVR_T_MtrA_RotrTemp, required-interface=FsftINVR_T_MtrA_RotrTemp
      PokeINVR_T_MtrA_RotrTemp: variation-point={short-label=vpPokeINVR_T_MtrA_RotrTemp, sw-syscond=1}, client-com-spec=PokeINVR_T_MtrA_RotrTemp, required-interface=PokeINVR_T_MtrA_RotrTemp
      TmotINVR_b_MtrA_RotrTemp: variation-point={short-label=vpTmotINVR_b_MtrA_RotrTemp, sw-syscond=1}, client-com-spec=TmotINVR_b_MtrA_RotrTemp, required-interface=TmotINVR_b_MtrA_RotrTemp
      PokeHMIR_b_MCPA_Service_Lamp_Request: variation-point={short-label=vpPokeHMIR_b_MCPA_Service_Lamp_Request, sw-syscond=1}, client-com-spec=PokeHMIR_b_MCPA_Service_Lamp_Request, required-interface=PokeHMIR_b_MCPA_Service_Lamp_Request
      PokeINVR_e_MtrB_6SOEnbl: client-com-spec=PokeINVR_e_MtrB_6SOEnbl, required-interface=PokeINVR_e_MtrB_6SOEnbl
      TmotINVR_b_MtrB_6SOEnbl: client-com-spec=TmotINVR_b_MtrB_6SOEnbl, required-interface=TmotINVR_b_MtrB_6SOEnbl
      FsftMSPR_dn_MtrB_AccelRaw: client-com-spec=FsftMSPR_dn_MtrB_AccelRaw, required-interface=FsftMSPR_dn_MtrB_AccelRaw
      PokeMSPR_dn_MtrB_AccelRaw: client-com-spec=PokeMSPR_dn_MtrB_AccelRaw, required-interface=PokeMSPR_dn_MtrB_AccelRaw
      TmotMSPR_b_MtrB_AccelRaw: client-com-spec=TmotMSPR_b_MtrB_AccelRaw, required-interface=TmotMSPR_b_MtrB_AccelRaw
      FsftMTIR_n_MtrBCapabilitySpd: client-com-spec=FsftMTIR_n_MtrBCapabilitySpd, required-interface=FsftMTIR_n_MtrBCapabilitySpd
      PokeMTIR_n_MtrBCapabilitySpd: client-com-spec=PokeMTIR_n_MtrBCapabilitySpd, required-interface=PokeMTIR_n_MtrBCapabilitySpd
      FsftMTIR_k_MtrBDeratingFactor: client-com-spec=FsftMTIR_k_MtrBDeratingFactor, required-interface=FsftMTIR_k_MtrBDeratingFactor
      PokeMTIR_k_MtrBDeratingFactor: client-com-spec=PokeMTIR_k_MtrBDeratingFactor, required-interface=PokeMTIR_k_MtrBDeratingFactor
      FsftINVR_e_MtrB_Dschrge_Stat: client-com-spec=FsftINVR_e_MtrB_Dschrge_Stat, required-interface=FsftINVR_e_MtrB_Dschrge_Stat
      PokeINVR_e_MtrB_Dschrge_Stat: client-com-spec=PokeINVR_e_MtrB_Dschrge_Stat, required-interface=PokeINVR_e_MtrB_Dschrge_Stat
      FsftINVR_b_MtrBFlt_HV_CntctrOpnRq: client-com-spec=FsftINVR_b_MtrBFlt_HV_CntctrOpnRq, required-interface=FsftINVR_b_MtrBFlt_HV_CntctrOpnRq
      PokeINVR_b_MtrBFlt_HV_CntctrOpnRq: client-com-spec=PokeINVR_b_MtrBFlt_HV_CntctrOpnRq, required-interface=PokeINVR_b_MtrBFlt_HV_CntctrOpnRq
      TmotINVR_b_MtrBFlt_HV_CntctrOpnRq: client-com-spec=TmotINVR_b_MtrBFlt_HV_CntctrOpnRq, required-interface=TmotINVR_b_MtrBFlt_HV_CntctrOpnRq
      FsftINVR_b_MCPB_HVILSts: client-com-spec=FsftINVR_b_MCPB_HVILSts, required-interface=FsftINVR_b_MCPB_HVILSts
      PokeINVR_e_MCPB_HVILSts: client-com-spec=PokeINVR_e_MCPB_HVILSts, required-interface=PokeINVR_e_MCPB_HVILSts
      FsftINVR_e_MtrB_InvrtrSt: client-com-spec=FsftINVR_e_MtrB_InvrtrSt, required-interface=FsftINVR_e_MtrB_InvrtrSt
      PokeINVR_e_MtrB_InvrtrSt: client-com-spec=PokeINVR_e_MtrB_InvrtrSt, required-interface=PokeINVR_e_MtrB_InvrtrSt
      TmotINVR_b_MtrB_InvrtrSt: client-com-spec=TmotINVR_b_MtrB_InvrtrSt, required-interface=TmotINVR_b_MtrB_InvrtrSt
      FsftMTIR_M_MtrB_MaxTorq: client-com-spec=FsftMTIR_M_MtrB_MaxTorq, required-interface=FsftMTIR_M_MtrB_MaxTorq
      PokeMTIR_M_MtrB_MaxTorq: client-com-spec=PokeMTIR_M_MtrB_MaxTorq, required-interface=PokeMTIR_M_MtrB_MaxTorq
      FsftMTIR_M_MtrB_MinTorq: client-com-spec=FsftMTIR_M_MtrB_MinTorq, required-interface=FsftMTIR_M_MtrB_MinTorq
      PokeMTIR_M_MtrB_MinTorq: client-com-spec=PokeMTIR_M_MtrB_MinTorq, required-interface=PokeMTIR_M_MtrB_MinTorq
      FsftMTIR_M_MtrBCapabilityMax: client-com-spec=FsftMTIR_M_MtrBCapabilityMax, required-interface=FsftMTIR_M_MtrBCapabilityMax
      PokeMTIR_M_MtrBCapabilityMax: client-com-spec=PokeMTIR_M_MtrBCapabilityMax, required-interface=PokeMTIR_M_MtrBCapabilityMax
      FsftMTIR_M_MtrBCapabilityMin: client-com-spec=FsftMTIR_M_MtrBCapabilityMin, required-interface=FsftMTIR_M_MtrBCapabilityMin
      PokeMTIR_M_MtrBCapabilityMin: client-com-spec=PokeMTIR_M_MtrBCapabilityMin, required-interface=PokeMTIR_M_MtrBCapabilityMin
      FsftMSPR_n_MtrB_SpdRaw: client-com-spec=FsftMSPR_n_MtrB_SpdRaw, required-interface=FsftMSPR_n_MtrB_SpdRaw
      PokeMSPR_n_MtrB_SpdRaw: client-com-spec=PokeMSPR_n_MtrB_SpdRaw, required-interface=PokeMSPR_n_MtrB_SpdRaw
      TmotMSPR_b_MtrB_SpdRaw: client-com-spec=TmotMSPR_b_MtrB_SpdRaw, required-interface=TmotMSPR_b_MtrB_SpdRaw
      FsftINVR_e_MCPB_SPT_State: client-com-spec=FsftINVR_e_MCPB_SPT_State, required-interface=FsftINVR_e_MCPB_SPT_State
      PokeINVR_e_MCPB_SPT_State: client-com-spec=PokeINVR_e_MCPB_SPT_State, required-interface=PokeINVR_e_MCPB_SPT_State
      TmotINVR_b_MCPB_SPT_State: client-com-spec=TmotINVR_b_MCPB_SPT_State, required-interface=TmotINVR_b_MCPB_SPT_State
      FsftMSPR_n_MaxP2SpdLmt: client-com-spec=FsftMSPR_n_MaxP2SpdLmt, required-interface=FsftMSPR_n_MaxP2SpdLmt
      PokeMSPR_n_MaxP2SpdLmt: client-com-spec=PokeMSPR_n_MaxP2SpdLmt, required-interface=PokeMSPR_n_MaxP2SpdLmt
      TmotMSPR_n_MaxP2SpdLmt: client-com-spec=TmotMSPR_n_MaxP2SpdLmt, required-interface=TmotMSPR_n_MaxP2SpdLmt
      FsftINVR_T_MtrB_Temp: client-com-spec=FsftINVR_T_MtrB_Temp, required-interface=FsftINVR_T_MtrB_Temp
      PokeINVR_T_MtrB_Temp: client-com-spec=PokeINVR_T_MtrB_Temp, required-interface=PokeINVR_T_MtrB_Temp
      TmotINVR_b_MtrB_Temp: client-com-spec=TmotINVR_b_MtrB_Temp, required-interface=TmotINVR_b_MtrB_Temp
      FsftMTIR_M_MtrB_TorqAchieved_AEMD: client-com-spec=FsftMTIR_M_MtrB_TorqAchieved_AEMD, required-interface=FsftMTIR_M_MtrB_TorqAchieved_AEMD
      PokeMTIR_M_MtrB_TorqAchieved_AEMD: client-com-spec=PokeMTIR_M_MtrB_TorqAchieved_AEMD, required-interface=PokeMTIR_M_MtrB_TorqAchieved_AEMD
      TmotMTIR_b_MtrB_TorqAchieved_AEMD: client-com-spec=TmotMTIR_b_MtrB_TorqAchieved_AEMD, required-interface=TmotMTIR_b_MtrB_TorqAchieved_AEMD
      FsftMTIR_M_MtrB_TorqAchieved: client-com-spec=FsftMTIR_M_MtrB_TorqAchieved, required-interface=FsftMTIR_M_MtrB_TorqAchieved
      PokeMTIR_M_MtrB_TorqAchieved: client-com-spec=PokeMTIR_M_MtrB_TorqAchieved, required-interface=PokeMTIR_M_MtrB_TorqAchieved
      FsftPPCR_b_Prmry_MPR_Pos_Sensor: client-com-spec=FsftPPCR_b_Prmry_MPR_Pos_Sensor, required-interface=FsftPPCR_b_Prmry_MPR_Pos_Sensor
      PokePPCR_e_Prmry_MPR_Pos_Sensor: client-com-spec=PokePPCR_e_Prmry_MPR_Pos_Sensor, required-interface=PokePPCR_e_Prmry_MPR_Pos_Sensor
      FsftPPCR_b_Prmry_Park_Pawl_flt_Stat: client-com-spec=FsftPPCR_b_Prmry_Park_Pawl_flt_Stat, required-interface=FsftPPCR_b_Prmry_Park_Pawl_flt_Stat
      PokePPCR_e_Prmry_Park_Pawl_flt_Stat: client-com-spec=PokePPCR_e_Prmry_Park_Pawl_flt_Stat, required-interface=PokePPCR_e_Prmry_Park_Pawl_flt_Stat
      FsftPPCR_b_Prmry_PP_Motor_Pos_Stat: client-com-spec=FsftPPCR_b_Prmry_PP_Motor_Pos_Stat, required-interface=FsftPPCR_b_Prmry_PP_Motor_Pos_Stat
      PokePPCR_e_Prmry_PP_Motor_Pos_Stat: client-com-spec=PokePPCR_e_Prmry_PP_Motor_Pos_Stat, required-interface=PokePPCR_e_Prmry_PP_Motor_Pos_Stat
      FsftPPCR_b_Prmry_PP_Pos_Sensor: client-com-spec=FsftPPCR_b_Prmry_PP_Pos_Sensor, required-interface=FsftPPCR_b_Prmry_PP_Pos_Sensor
      PokePPCR_e_Prmry_PP_Pos_Sensor: client-com-spec=PokePPCR_e_Prmry_PP_Pos_Sensor, required-interface=PokePPCR_e_Prmry_PP_Pos_Sensor
      FsftPPCR_b_Prmry_Park_Pawl_Stat: client-com-spec=FsftPPCR_b_Prmry_Park_Pawl_Stat, required-interface=FsftPPCR_b_Prmry_Park_Pawl_Stat
      PokePPCR_e_Prmry_Park_Pawl_Stat: client-com-spec=PokePPCR_e_Prmry_Park_Pawl_Stat, required-interface=PokePPCR_e_Prmry_Park_Pawl_Stat
      FsftINVR_T_MtrB_CtrlBoard_Temp: client-com-spec=FsftINVR_T_MtrB_CtrlBoard_Temp, required-interface=FsftINVR_T_MtrB_CtrlBoard_Temp
      PokeINVR_T_MtrB_CtrlBoard_Temp: client-com-spec=PokeINVR_T_MtrB_CtrlBoard_Temp, required-interface=PokeINVR_T_MtrB_CtrlBoard_Temp
      TmotINVR_b_MtrB_CtrlBoard_Temp: client-com-spec=TmotINVR_b_MtrB_CtrlBoard_Temp, required-interface=TmotINVR_b_MtrB_CtrlBoard_Temp
      FsftINVR_I_MtrB_DC_Crnt: client-com-spec=FsftINVR_I_MtrB_DC_Crnt, required-interface=FsftINVR_I_MtrB_DC_Crnt
      PokeINVR_I_MtrB_DC_Crnt: client-com-spec=PokeINVR_I_MtrB_DC_Crnt, required-interface=PokeINVR_I_MtrB_DC_Crnt
      TmotINVR_b_MtrB_DC_Crnt: client-com-spec=TmotINVR_b_MtrB_DC_Crnt, required-interface=TmotINVR_b_MtrB_DC_Crnt
      FsftINVR_U_MtrB_DC_Volt: client-com-spec=FsftINVR_U_MtrB_DC_Volt, required-interface=FsftINVR_U_MtrB_DC_Volt
      PokeINVR_U_MtrB_DC_Volt: client-com-spec=PokeINVR_U_MtrB_DC_Volt, required-interface=PokeINVR_U_MtrB_DC_Volt
      TmotINVR_b_MtrB_DC_Volt: client-com-spec=TmotINVR_b_MtrB_DC_Volt, required-interface=TmotINVR_b_MtrB_DC_Volt
      PokeINVR_e_MtrB_DrtRsn: client-com-spec=PokeINVR_e_MtrB_DrtRsn, required-interface=PokeINVR_e_MtrB_DrtRsn
      FsftINVR_T_MtrB_InvrtrTemp: client-com-spec=FsftINVR_T_MtrB_InvrtrTemp, required-interface=FsftINVR_T_MtrB_InvrtrTemp
      PokeINVR_T_MtrB_InvrtrTemp: client-com-spec=PokeINVR_T_MtrB_InvrtrTemp, required-interface=PokeINVR_T_MtrB_InvrtrTemp
      TmotINVR_b_MtrB_InvrtrTemp: client-com-spec=TmotINVR_b_MtrB_InvrtrTemp, required-interface=TmotINVR_b_MtrB_InvrtrTemp
      FsftINVR_T_MtrBBusBarTemp: client-com-spec=FsftINVR_T_MtrBBusBarTemp, required-interface=FsftINVR_T_MtrBBusBarTemp
      PokeINVR_T_MtrBBusBarTemp: client-com-spec=PokeINVR_T_MtrBBusBarTemp, required-interface=PokeINVR_T_MtrBBusBarTemp
      FsftINVR_T_MtrB_RotrTemp: client-com-spec=FsftINVR_T_MtrB_RotrTemp, required-interface=FsftINVR_T_MtrB_RotrTemp
      PokeINVR_T_MtrB_RotrTemp: client-com-spec=PokeINVR_T_MtrB_RotrTemp, required-interface=PokeINVR_T_MtrB_RotrTemp
      TmotINVR_b_MtrB_RotrTemp: client-com-spec=TmotINVR_b_MtrB_RotrTemp, required-interface=TmotINVR_b_MtrB_RotrTemp
      PokeHMIR_b_MCPB_Service_Lamp_Request: client-com-spec=PokeHMIR_b_MCPB_Service_Lamp_Request, required-interface=PokeHMIR_b_MCPB_Service_Lamp_Request
    behavior IB_CR4B_FUNC: data-type-mapping=msADTtoIDTMapping, handle-termination-and-restart=NO-SUPPORT
      timing event Event_FastTEF: start-on-event=CR4B_FUNC_FastTEF, period=0.005
      init event Event_CR4B_FUNC_ac_Init: start-on-event=CR4B_FUNC_ac_Init
      runnable CR4B_FUNC_ac_Init
      runnable CR4B_FUNC_FastTEF
        data-receive-point-by-arguments:
          141 x access:
            IN_VeCANR_e_CanLocEnblStatus_VeCANR_e_CanLocEnblStatus: accessed-variable=VeCANR_e_CanLocEnblStatus.VeCANR_e_CanLocEnblStatus
            IN_VeCRDB_I_MCPA_DC_Current_P_Value: accessed-variable=VeCRDB_I_MCPA_DC_Current_P.Value, variation-point={short-label=vpIN_VeCRDB_I_MCPA_DC_Current_P_Value, sw-syscond=1}
            IN_VeCRDB_I_MCPB_DC_Current_P_Value: accessed-variable=VeCRDB_I_MCPB_DC_Current_P.Value
            IN_VeCRDB_M_MCPA_MaxTorq_P_Value: accessed-variable=VeCRDB_M_MCPA_MaxTorq_P.Value, variation-point={short-label=vpIN_VeCRDB_M_MCPA_MaxTorq_P_Value, sw-syscond=1}
            IN_VeCRDB_M_MCPA_MinTorq_P_Value: accessed-variable=VeCRDB_M_MCPA_MinTorq_P.Value, variation-point={short-label=vpIN_VeCRDB_M_MCPA_MinTorq_P_Value, sw-syscond=1}
            IN_VeCRDB_M_MCPA_MtrMaxCpbltyTrq_P_Value: accessed-variable=VeCRDB_M_MCPA_MtrMaxCpbltyTrq_P.Value, variation-point={short-label=vpIN_VeCRDB_M_MCPA_MtrMaxCpbltyTrq_P_Value, sw-syscond=1}
            IN_VeCRDB_M_MCPA_MtrMinCpbltyTrq_P_Value: accessed-variable=VeCRDB_M_MCPA_MtrMinCpbltyTrq_P.Value, variation-point={short-label=vpIN_VeCRDB_M_MCPA_MtrMinCpbltyTrq_P_Value, sw-syscond=1}
            IN_VeCRDB_M_MCPA_TorqAchved_AEMD_P_Value: accessed-variable=VeCRDB_M_MCPA_TorqAchved_AEMD_P.Value, variation-point={short-label=vpIN_VeCRDB_M_MCPA_TorqAchved_AEMD_P_Value, sw-syscond=1}
            IN_VeCRDB_M_MCPA_Torque_Achieved_P_Value: accessed-variable=VeCRDB_M_MCPA_Torque_Achieved_P.Value, variation-point={short-label=vpIN_VeCRDB_M_MCPA_Torque_Achieved_P_Value, sw-syscond=1}
            IN_VeCRDB_M_MCPB_MaxTorq_P_Value: accessed-variable=VeCRDB_M_MCPB_MaxTorq_P.Value
            IN_VeCRDB_M_MCPB_MinTorq_P_Value: accessed-variable=VeCRDB_M_MCPB_MinTorq_P.Value
            IN_VeCRDB_M_MCPB_MtrMaxCpbltyTrq_P_Value: accessed-variable=VeCRDB_M_MCPB_MtrMaxCpbltyTrq_P.Value
            IN_VeCRDB_M_MCPB_MtrMinCpbltyTrq_P_Value: accessed-variable=VeCRDB_M_MCPB_MtrMinCpbltyTrq_P.Value
            IN_VeCRDB_M_MCPB_TorqAchved_AEMD_P_Value: accessed-variable=VeCRDB_M_MCPB_TorqAchved_AEMD_P.Value
            IN_VeCRDB_M_MCPB_Torque_Achieved_P_Value: accessed-variable=VeCRDB_M_MCPB_Torque_Achieved_P.Value
            IN_VeCRDB_T_MCPACtrlBoarTempP_Value: accessed-variable=VeCRDB_T_MCPACtrlBoarTempP.Value, variation-point={short-label=vpIN_VeCRDB_T_MCPACtrlBoarTempP_Value, sw-syscond=1}
            IN_VeCRDB_T_MCPAPIMDCSdBusTmpP_Value: accessed-variable=VeCRDB_T_MCPAPIMDCSdBusTmpP.Value, variation-point={short-label=vpIN_VeCRDB_T_MCPAPIMDCSdBusTmpP_Value, sw-syscond=1}
            IN_VeCRDB_T_MCPARotorTemp_P_Value: accessed-variable=VeCRDB_T_MCPARotorTemp_P.Value, variation-point={short-label=vpIN_VeCRDB_T_MCPARotorTemp_P_Value, sw-syscond=1}
            IN_VeCRDB_T_MCPA_InvertTemp_P_Value: accessed-variable=VeCRDB_T_MCPA_InvertTemp_P.Value, variation-point={short-label=vpIN_VeCRDB_T_MCPA_InvertTemp_P_Value, sw-syscond=1}
            IN_VeCRDB_T_MCPA_Temp_P_Value: accessed-variable=VeCRDB_T_MCPA_Temp_P.Value, variation-point={short-label=vpIN_VeCRDB_T_MCPA_Temp_P_Value, sw-syscond=1}
            IN_VeCRDB_T_MCPBPIMDCSdBusTmpP_Value: accessed-variable=VeCRDB_T_MCPBPIMDCSdBusTmpP.Value
            IN_VeCRDB_T_MCPBRotorTemp_P_Value: accessed-variable=VeCRDB_T_MCPBRotorTemp_P.Value
            IN_VeCRDB_T_MCPB_InvertTemp_P_Value: accessed-variable=VeCRDB_T_MCPB_InvertTemp_P.Value
            IN_VeCRDB_U_MCPA_DC_Voltage_P_Value: accessed-variable=VeCRDB_U_MCPA_DC_Voltage_P.Value, variation-point={short-label=vpIN_VeCRDB_U_MCPA_DC_Voltage_P_Value, sw-syscond=1}
            IN_VeCRDB_U_MCPB_CpbltySpdDvVolt_P_Value: accessed-variable=VeCRDB_U_MCPB_CpbltySpdDvVolt_P.Value
            IN_VeCRDB_U_MCPB_DC_Voltage_P_Value: accessed-variable=VeCRDB_U_MCPB_DC_Voltage_P.Value
            IN_VeCRDB_b_MCPAServLampReq_P_Value: accessed-variable=VeCRDB_b_MCPAServLampReq_P.Value, variation-point={short-label=vpIN_VeCRDB_b_MCPAServLampReq_P_Value, sw-syscond=1}
            IN_VeCRDB_b_MCPA_DC_Crrnt_V_P_Value: accessed-variable=VeCRDB_b_MCPA_DC_Crrnt_V_P.Value, variation-point={short-label=vpIN_VeCRDB_b_MCPA_DC_Crrnt_V_P_Value, sw-syscond=1}
            IN_VeCRDB_b_MCPA_DC_Volt_V_P_Value: accessed-variable=VeCRDB_b_MCPA_DC_Volt_V_P.Value, variation-point={short-label=vpIN_VeCRDB_b_MCPA_DC_Volt_V_P_Value, sw-syscond=1}
            IN_VeCRDB_b_MCPA_HV_CnctrOpn_Req_P_Value: accessed-variable=VeCRDB_b_MCPA_HV_CnctrOpn_Req_P.Value, variation-point={short-label=vpIN_VeCRDB_b_MCPA_HV_CnctrOpn_Req_P_Value, sw-syscond=1}
            IN_VeCRDB_b_MCPA_RPM_V_P_Value: accessed-variable=VeCRDB_b_MCPA_RPM_V_P.Value, variation-point={short-label=vpIN_VeCRDB_b_MCPA_RPM_V_P_Value, sw-syscond=1}
            IN_VeCRDB_b_MCPA_Torque_Achved_V_P_Value: accessed-variable=VeCRDB_b_MCPA_Torque_Achved_V_P.Value, variation-point={short-label=vpIN_VeCRDB_b_MCPA_Torque_Achved_V_P_Value, sw-syscond=1}
            IN_VeCRDB_b_MCPBServLampReq_P_Value: accessed-variable=VeCRDB_b_MCPBServLampReq_P.Value
            IN_VeCRDB_b_MCPB_DC_Crrnt_V_P_Value: accessed-variable=VeCRDB_b_MCPB_DC_Crrnt_V_P.Value
            IN_VeCRDB_b_MCPB_DC_Volt_V_P_Value: accessed-variable=VeCRDB_b_MCPB_DC_Volt_V_P.Value
            IN_VeCRDB_b_MCPB_HV_CnctrOpn_Req_P_Value: accessed-variable=VeCRDB_b_MCPB_HV_CnctrOpn_Req_P.Value
            IN_VeCRDB_e_MCPA_DerateResn_P_Value: accessed-variable=VeCRDB_e_MCPA_DerateResn_P.Value, variation-point={short-label=vpIN_VeCRDB_e_MCPA_DerateResn_P_Value, sw-syscond=1}
            IN_VeCRDB_e_MCPB_DerateResn_P_Value: accessed-variable=VeCRDB_e_MCPB_DerateResn_P.Value
            IN_VeCRDB_h_MCPA_DeratingFactor_P_Value: accessed-variable=VeCRDB_h_MCPA_DeratingFactor_P.Value, variation-point={short-label=vpIN_VeCRDB_h_MCPA_DeratingFactor_P_Value, sw-syscond=1}
            IN_VeCRDB_h_MCPB_DeratingFactor_P_Value: accessed-variable=VeCRDB_h_MCPB_DeratingFactor_P.Value
            IN_VeCRDB_n_MCPA_CpbltySpdDvVolt_P_Value: accessed-variable=VeCRDB_n_MCPA_CpbltySpdDvVolt_P.Value, variation-point={short-label=vpIN_VeCRDB_n_MCPA_CpbltySpdDvVolt_P_Value, sw-syscond=1}
            IN_VeCRDB_n_MCPA_RPM_P_Value: accessed-variable=VeCRDB_n_MCPA_RPM_P.Value, variation-point={short-label=vpIN_VeCRDB_n_MCPA_RPM_P_Value, sw-syscond=1}
            IN_VeCRDB_n_MCPA_Spd_Lim_P_Value: accessed-variable=VeCRDB_n_MCPA_Spd_Lim_P.Value, variation-point={short-label=vpIN_VeCRDB_n_MCPA_Spd_Lim_P_Value, sw-syscond=1}
            IN_VeCRDB_n_MCPB_RPM_P_Value: accessed-variable=VeCRDB_n_MCPB_RPM_P.Value
            IN_VeCRDB_n_MCPB_Spd_Lim_P_Value: accessed-variable=VeCRDB_n_MCPB_Spd_Lim_P.Value
            IN_VeCRDB_y_MCPACtrlBoarTempP_SigSts_Value: accessed-variable=VeCRDB_y_MCPACtrlBoarTempP_SigSts.Value, variation-point={short-label=vpIN_VeCRDB_y_MCPACtrlBoarTempP_SigSts_Value, sw-syscond=1}
            IN_VeCRDB_y_MCPAPIMDCSdBusTmpP_SigSts_Value: accessed-variable=VeCRDB_y_MCPAPIMDCSdBusTmpP_SigSts.Value, variation-point={short-label=vpIN_VeCRDB_y_MCPAPIMDCSdBusTmpP_SigSts_Value, sw-syscond=1}
            IN_VeCRDB_y_MCPARotorTemp_P_SigSts_Value: accessed-variable=VeCRDB_y_MCPARotorTemp_P_SigSts.Value, variation-point={short-label=vpIN_VeCRDB_y_MCPARotorTemp_P_SigSts_Value, sw-syscond=1}
            IN_VeCRDB_y_MCPAServLampReq_P_SigSts_Value: accessed-variable=VeCRDB_y_MCPAServLampReq_P_SigSts.Value, variation-point={short-label=vpIN_VeCRDB_y_MCPAServLampReq_P_SigSts_Value, sw-syscond=1}
            IN_VeCRDB_y_MCPA_6SO_Status_P_Value: accessed-variable=VeCRDB_y_MCPA_6SO_Status_P.Value, variation-point={short-label=vpIN_VeCRDB_y_MCPA_6SO_Status_P_Value, sw-syscond=1}
            IN_VeCRDB_y_MCPA_6SO_Status_P_SigSts_Value: accessed-variable=VeCRDB_y_MCPA_6SO_Status_P_SigSts.Value, variation-point={short-label=vpIN_VeCRDB_y_MCPA_6SO_Status_P_SigSts_Value, sw-syscond=1}
            IN_VeCRDB_y_MCPA_AccelRaw_P_Value: accessed-variable=VeCRDB_y_MCPA_AccelRaw_P.Value, variation-point={short-label=vpIN_VeCRDB_y_MCPA_AccelRaw_P_Value, sw-syscond=1}
            IN_VeCRDB_y_MCPA_AccelRaw_P_SigSts_Value: accessed-variable=VeCRDB_y_MCPA_AccelRaw_P_SigSts.Value, variation-point={short-label=vpIN_VeCRDB_y_MCPA_AccelRaw_P_SigSts_Value, sw-syscond=1}
            IN_VeCRDB_y_MCPA_CpbltySpdDvVolt_P_SigSts_Value: accessed-variable=VeCRDB_y_MCPA_CpbltySpdDvVolt_P_SigSts.Value, variation-point={short-label=vpIN_VeCRDB_y_MCPA_CpbltySpdDvVolt_P_SigSts_Value, sw-syscond=1}
            IN_VeCRDB_y_MCPA_DC_Current_P_SigSts_Value: accessed-variable=VeCRDB_y_MCPA_DC_Current_P_SigSts.Value, variation-point={short-label=vpIN_VeCRDB_y_MCPA_DC_Current_P_SigSts_Value, sw-syscond=1}
            IN_VeCRDB_y_MCPA_DC_Voltage_P_SigSts_Value: accessed-variable=VeCRDB_y_MCPA_DC_Voltage_P_SigSts.Value, variation-point={short-label=vpIN_VeCRDB_y_MCPA_DC_Voltage_P_SigSts_Value, sw-syscond=1}
            IN_VeCRDB_y_MCPA_DerateResn_P_SigSts_Value: accessed-variable=VeCRDB_y_MCPA_DerateResn_P_SigSts.Value, variation-point={short-label=vpIN_VeCRDB_y_MCPA_DerateResn_P_SigSts_Value, sw-syscond=1}
            IN_VeCRDB_y_MCPA_DeratingFactor_P_SigSts_Value: accessed-variable=VeCRDB_y_MCPA_DeratingFactor_P_SigSts.Value, variation-point={short-label=vpIN_VeCRDB_y_MCPA_DeratingFactor_P_SigSts_Value, sw-syscond=1}
            IN_VeCRDB_y_MCPA_Dschrge_Status_P_Value: accessed-variable=VeCRDB_y_MCPA_Dschrge_Status_P.Value, variation-point={short-label=vpIN_VeCRDB_y_MCPA_Dschrge_Status_P_Value, sw-syscond=1}
            IN_VeCRDB_y_MCPA_Dschrge_Status_P_SigSts_Value: accessed-variable=VeCRDB_y_MCPA_Dschrge_Status_P_SigSts.Value, variation-point={short-label=vpIN_VeCRDB_y_MCPA_Dschrge_Status_P_SigSts_Value, sw-syscond=1}
            IN_VeCRDB_y_MCPA_HV_CnctrOpn_Req_P_SigSts_Value: accessed-variable=VeCRDB_y_MCPA_HV_CnctrOpn_Req_P_SigSts.Value, variation-point={short-label=vpIN_VeCRDB_y_MCPA_HV_CnctrOpn_Req_P_SigSts_Value, sw-syscond=1}
            IN_VeCRDB_y_MCPA_InterlockSts_P_Value: accessed-variable=VeCRDB_y_MCPA_InterlockSts_P.Value, variation-point={short-label=vpIN_VeCRDB_y_MCPA_InterlockSts_P_Value, sw-syscond=1}
            IN_VeCRDB_y_MCPA_InterlockSts_P_SigSts_Value: accessed-variable=VeCRDB_y_MCPA_InterlockSts_P_SigSts.Value, variation-point={short-label=vpIN_VeCRDB_y_MCPA_InterlockSts_P_SigSts_Value, sw-syscond=1}
            IN_VeCRDB_y_MCPA_InvertTemp_P_SigSts_Value: accessed-variable=VeCRDB_y_MCPA_InvertTemp_P_SigSts.Value, variation-point={short-label=vpIN_VeCRDB_y_MCPA_InvertTemp_P_SigSts_Value, sw-syscond=1}
            IN_VeCRDB_y_MCPA_Invrtr_State_P_Value: accessed-variable=VeCRDB_y_MCPA_Invrtr_State_P.Value, variation-point={short-label=vpIN_VeCRDB_y_MCPA_Invrtr_State_P_Value, sw-syscond=1}
            IN_VeCRDB_y_MCPA_Invrtr_State_P_SigSts_Value: accessed-variable=VeCRDB_y_MCPA_Invrtr_State_P_SigSts.Value, variation-point={short-label=vpIN_VeCRDB_y_MCPA_Invrtr_State_P_SigSts_Value, sw-syscond=1}
            IN_VeCRDB_y_MCPA_MaxTorq_P_SigSts_Value: accessed-variable=VeCRDB_y_MCPA_MaxTorq_P_SigSts.Value, variation-point={short-label=vpIN_VeCRDB_y_MCPA_MaxTorq_P_SigSts_Value, sw-syscond=1}
            IN_VeCRDB_y_MCPA_MinTorq_P_SigSts_Value: accessed-variable=VeCRDB_y_MCPA_MinTorq_P_SigSts.Value, variation-point={short-label=vpIN_VeCRDB_y_MCPA_MinTorq_P_SigSts_Value, sw-syscond=1}
            IN_VeCRDB_y_MCPA_MtrMaxCpbltyTrq_P_SigSts_Value: accessed-variable=VeCRDB_y_MCPA_MtrMaxCpbltyTrq_P_SigSts.Value, variation-point={short-label=vpIN_VeCRDB_y_MCPA_MtrMaxCpbltyTrq_P_SigSts_Value, sw-syscond=1}
            IN_VeCRDB_y_MCPA_MtrMinCpbltyTrq_P_SigSts_Value: accessed-variable=VeCRDB_y_MCPA_MtrMinCpbltyTrq_P_SigSts.Value, variation-point={short-label=vpIN_VeCRDB_y_MCPA_MtrMinCpbltyTrq_P_SigSts_Value, sw-syscond=1}
            IN_VeCRDB_y_MCPA_RPM_P_SigSts_Value: accessed-variable=VeCRDB_y_MCPA_RPM_P_SigSts.Value, variation-point={short-label=vpIN_VeCRDB_y_MCPA_RPM_P_SigSts_Value, sw-syscond=1}
            IN_VeCRDB_y_MCPA_RPM_V_P_SigSts_Value: accessed-variable=VeCRDB_y_MCPA_RPM_V_P_SigSts.Value, variation-point={short-label=vpIN_VeCRDB_y_MCPA_RPM_V_P_SigSts_Value, sw-syscond=1}
            IN_VeCRDB_y_MCPA_SPT_Stat_P_Value: accessed-variable=VeCRDB_y_MCPA_SPT_Stat_P.Value, variation-point={short-label=vpIN_VeCRDB_y_MCPA_SPT_Stat_P_Value, sw-syscond=1}
            IN_VeCRDB_y_MCPA_SPT_Stat_P_SigSts_Value: accessed-variable=VeCRDB_y_MCPA_SPT_Stat_P_SigSts.Value, variation-point={short-label=vpIN_VeCRDB_y_MCPA_SPT_Stat_P_SigSts_Value, sw-syscond=1}
            IN_VeCRDB_y_MCPA_Spd_Lim_P_SigSts_Value: accessed-variable=VeCRDB_y_MCPA_Spd_Lim_P_SigSts.Value, variation-point={short-label=vpIN_VeCRDB_y_MCPA_Spd_Lim_P_SigSts_Value, sw-syscond=1}
            IN_VeCRDB_y_MCPA_Temp_P_SigSts_Value: accessed-variable=VeCRDB_y_MCPA_Temp_P_SigSts.Value, variation-point={short-label=vpIN_VeCRDB_y_MCPA_Temp_P_SigSts_Value, sw-syscond=1}
            IN_VeCRDB_y_MCPA_TorqAchved_AEMD_P_SigSts_Value: accessed-variable=VeCRDB_y_MCPA_TorqAchved_AEMD_P_SigSts.Value, variation-point={short-label=vpIN_VeCRDB_y_MCPA_TorqAchved_AEMD_P_SigSts_Value, sw-syscond=1}
            IN_VeCRDB_y_MCPA_Torque_Achieved_P_SigSts_Value: accessed-variable=VeCRDB_y_MCPA_Torque_Achieved_P_SigSts.Value, variation-point={short-label=vpIN_VeCRDB_y_MCPA_Torque_Achieved_P_SigSts_Value, sw-syscond=1}
            IN_VeCRDB_y_MCPA_Torque_Achved_V_P_SigSts_Value: accessed-variable=VeCRDB_y_MCPA_Torque_Achved_V_P_SigSts.Value, variation-point={short-label=vpIN_VeCRDB_y_MCPA_Torque_Achved_V_P_SigSts_Value, sw-syscond=1}
            IN_VeCRDB_y_MCPBCtrlBoarTempP_Value: accessed-variable=VeCRDB_y_MCPBCtrlBoarTempP.Value
            IN_VeCRDB_y_MCPBCtrlBoarTempP_SigSts_Value: accessed-variable=VeCRDB_y_MCPBCtrlBoarTempP_SigSts.Value
            IN_VeCRDB_y_MCPBPIMDCSdBusTmpP_SigSts_Value: accessed-variable=VeCRDB_y_MCPBPIMDCSdBusTmpP_SigSts.Value
            IN_VeCRDB_y_MCPBRotorTemp_P_SigSts_Value: accessed-variable=VeCRDB_y_MCPBRotorTemp_P_SigSts.Value
            IN_VeCRDB_y_MCPBServLampReq_P_SigSts_Value: accessed-variable=VeCRDB_y_MCPBServLampReq_P_SigSts.Value
            IN_VeCRDB_y_MCPB_6SO_Status_P_Value: accessed-variable=VeCRDB_y_MCPB_6SO_Status_P.Value
            IN_VeCRDB_y_MCPB_6SO_Status_P_SigSts_Value: accessed-variable=VeCRDB_y_MCPB_6SO_Status_P_SigSts.Value
            IN_VeCRDB_y_MCPB_AccelRaw_P_Value: accessed-variable=VeCRDB_y_MCPB_AccelRaw_P.Value
            IN_VeCRDB_y_MCPB_AccelRaw_P_SigSts_Value: accessed-variable=VeCRDB_y_MCPB_AccelRaw_P_SigSts.Value
            IN_VeCRDB_y_MCPB_CpbltySpdDvVolt_P_SigSts_Value: accessed-variable=VeCRDB_y_MCPB_CpbltySpdDvVolt_P_SigSts.Value
            IN_VeCRDB_y_MCPB_DC_Current_P_SigSts_Value: accessed-variable=VeCRDB_y_MCPB_DC_Current_P_SigSts.Value
            IN_VeCRDB_y_MCPB_DC_Voltage_P_SigSts_Value: accessed-variable=VeCRDB_y_MCPB_DC_Voltage_P_SigSts.Value
            IN_VeCRDB_y_MCPB_DerateResn_P_SigSts_Value: accessed-variable=VeCRDB_y_MCPB_DerateResn_P_SigSts.Value
            IN_VeCRDB_y_MCPB_DeratingFactor_P_SigSts_Value: accessed-variable=VeCRDB_y_MCPB_DeratingFactor_P_SigSts.Value
            IN_VeCRDB_y_MCPB_Dschrge_Status_P_Value: accessed-variable=VeCRDB_y_MCPB_Dschrge_Status_P.Value
            IN_VeCRDB_y_MCPB_Dschrge_Status_P_SigSts_Value: accessed-variable=VeCRDB_y_MCPB_Dschrge_Status_P_SigSts.Value
            IN_VeCRDB_y_MCPB_HV_CnctrOpn_Req_P_SigSts_Value: accessed-variable=VeCRDB_y_MCPB_HV_CnctrOpn_Req_P_SigSts.Value
            IN_VeCRDB_y_MCPB_InterlockSts_P_Value: accessed-variable=VeCRDB_y_MCPB_InterlockSts_P.Value
            IN_VeCRDB_y_MCPB_InterlockSts_P_SigSts_Value: accessed-variable=VeCRDB_y_MCPB_InterlockSts_P_SigSts.Value
            IN_VeCRDB_y_MCPB_InvertTemp_P_SigSts_Value: accessed-variable=VeCRDB_y_MCPB_InvertTemp_P_SigSts.Value
            IN_VeCRDB_y_MCPB_Invrtr_State_P_Value: accessed-variable=VeCRDB_y_MCPB_Invrtr_State_P.Value
            IN_VeCRDB_y_MCPB_Invrtr_State_P_SigSts_Value: accessed-variable=VeCRDB_y_MCPB_Invrtr_State_P_SigSts.Value
            IN_VeCRDB_y_MCPB_MaxTorq_P_SigSts_Value: accessed-variable=VeCRDB_y_MCPB_MaxTorq_P_SigSts.Value
            IN_VeCRDB_y_MCPB_MinTorq_P_SigSts_Value: accessed-variable=VeCRDB_y_MCPB_MinTorq_P_SigSts.Value
            IN_VeCRDB_y_MCPB_MtrMaxCpbltyTrq_P_SigSts_Value: accessed-variable=VeCRDB_y_MCPB_MtrMaxCpbltyTrq_P_SigSts.Value
            IN_VeCRDB_y_MCPB_MtrMinCpbltyTrq_P_SigSts_Value: accessed-variable=VeCRDB_y_MCPB_MtrMinCpbltyTrq_P_SigSts.Value
            IN_VeCRDB_y_MCPB_RPM_P_SigSts_Value: accessed-variable=VeCRDB_y_MCPB_RPM_P_SigSts.Value
            IN_VeCRDB_y_MCPB_SPT_Stat_P_Value: accessed-variable=VeCRDB_y_MCPB_SPT_Stat_P.Value
            IN_VeCRDB_y_MCPB_SPT_Stat_P_SigSts_Value: accessed-variable=VeCRDB_y_MCPB_SPT_Stat_P_SigSts.Value
            IN_VeCRDB_y_MCPB_Spd_Lim_P_SigSts_Value: accessed-variable=VeCRDB_y_MCPB_Spd_Lim_P_SigSts.Value
            IN_VeCRDB_y_MCPB_Temp_P_Value: accessed-variable=VeCRDB_y_MCPB_Temp_P.Value
            IN_VeCRDB_y_MCPB_Temp_P_SigSts_Value: accessed-variable=VeCRDB_y_MCPB_Temp_P_SigSts.Value
            IN_VeCRDB_y_MCPB_TorqAchved_AEMD_P_SigSts_Value: accessed-variable=VeCRDB_y_MCPB_TorqAchved_AEMD_P_SigSts.Value
            IN_VeCRDB_y_MCPB_Torque_Achieved_P_SigSts_Value: accessed-variable=VeCRDB_y_MCPB_Torque_Achieved_P_SigSts.Value
            IN_VeCRDB_y_MPR_PosSensor_P_Value: accessed-variable=VeCRDB_y_MPR_PosSensor_P.Value
            IN_VeCRDB_y_MPR_PosSensor_P_SigSts_Value: accessed-variable=VeCRDB_y_MPR_PosSensor_P_SigSts.Value
            IN_VeCRDB_y_PlockFailSts_P_Value: accessed-variable=VeCRDB_y_PlockFailSts_P.Value
            IN_VeCRDB_y_PlockFailSts_P_SigSts_Value: accessed-variable=VeCRDB_y_PlockFailSts_P_SigSts.Value
            IN_VeCRDB_y_Plock_MotorPosSts_P_Value: accessed-variable=VeCRDB_y_Plock_MotorPosSts_P.Value
            IN_VeCRDB_y_Plock_MotorPosSts_P_SigSts_Value: accessed-variable=VeCRDB_y_Plock_MotorPosSts_P_SigSts.Value
            IN_VeCRDB_y_Plock_PosSensor_P_Value: accessed-variable=VeCRDB_y_Plock_PosSensor_P.Value
            IN_VeCRDB_y_Plock_PosSensor_P_SigSts_Value: accessed-variable=VeCRDB_y_Plock_PosSensor_P_SigSts.Value
            IN_VeCRDB_y_Plock_fdbk_sts_P_Value: accessed-variable=VeCRDB_y_Plock_fdbk_sts_P.Value
            IN_VeCRDB_y_Plock_fdbk_sts_P_SigSts_Value: accessed-variable=VeCRDB_y_Plock_fdbk_sts_P_SigSts.Value
            IN_VeSR1B_b_MCPA_AccelRawV_P_FD16_Value: accessed-variable=VeSR1B_b_MCPA_AccelRawV_P_FD16.Value, variation-point={short-label=vpIN_VeSR1B_b_MCPA_AccelRawV_P_FD16_Value, sw-syscond=1}
            IN_VeSR1B_b_MCPA_RPM_V_P_FD16_Value: accessed-variable=VeSR1B_b_MCPA_RPM_V_P_FD16.Value, variation-point={short-label=vpIN_VeSR1B_b_MCPA_RPM_V_P_FD16_Value, sw-syscond=1}
            IN_VeSR1B_b_MCPA_Torque_Achved_V_P_FD16_Value: accessed-variable=VeSR1B_b_MCPA_Torque_Achved_V_P_FD16.Value, variation-point={short-label=vpIN_VeSR1B_b_MCPA_Torque_Achved_V_P_FD16_Value, sw-syscond=1}
            IN_VeSR1B_b_MCPA_TrqAchvd_AEMD_V_P_FD16_Value: accessed-variable=VeSR1B_b_MCPA_TrqAchvd_AEMD_V_P_FD16.Value, variation-point={short-label=vpIN_VeSR1B_b_MCPA_TrqAchvd_AEMD_V_P_FD16_Value, sw-syscond=1}
            IN_VeSR1B_b_MCPB_AccelRawV_P_FD16_Value: accessed-variable=VeSR1B_b_MCPB_AccelRawV_P_FD16.Value
            IN_VeSR1B_b_MCPB_RPM_V_P_FD16_Value: accessed-variable=VeSR1B_b_MCPB_RPM_V_P_FD16.Value
            IN_VeSR1B_b_MCPB_Torque_Achved_V_P_FD16_Value: accessed-variable=VeSR1B_b_MCPB_Torque_Achved_V_P_FD16.Value
            IN_VeSR1B_b_MCPB_TrqAchvd_AEMD_V_P_FD16_Value: accessed-variable=VeSR1B_b_MCPB_TrqAchvd_AEMD_V_P_FD16.Value
            IN_VeSR1B_b_PRNDFailSts_Value: accessed-variable=VeSR1B_b_PRNDFailSts.Value
            IN_VeSR1B_b_PRNDdisplayFailSts_Value: accessed-variable=VeSR1B_b_PRNDdisplayFailSts.Value
            IN_VeSR1B_y_APCM_Stat_FD16_Value: accessed-variable=VeSR1B_y_APCM_Stat_FD16.Value
            IN_VeSR1B_y_APCM_Stat_FD16_SigSts_Value: accessed-variable=VeSR1B_y_APCM_Stat_FD16_SigSts.Value
            IN_VeSR1B_y_MCPA_MtrIndex_P_FD16_Value: accessed-variable=VeSR1B_y_MCPA_MtrIndex_P_FD16.Value, variation-point={short-label=vpIN_VeSR1B_y_MCPA_MtrIndex_P_FD16_Value, sw-syscond=1}
            IN_VeSR1B_y_MCPB_MtrIndex_P_FD16_Value: accessed-variable=VeSR1B_y_MCPB_MtrIndex_P_FD16.Value
            IN_VeSR1B_y_PRNDFailSts_SigSts_Value: accessed-variable=VeSR1B_y_PRNDFailSts_SigSts.Value
            IN_VeSR1B_y_PRNDdisplayFailSts_SigSts_Value: accessed-variable=VeSR1B_y_PRNDdisplayFailSts_SigSts.Value
            IN_VeSR1B_y_ShiftLeverPositionReq_Value: accessed-variable=VeSR1B_y_ShiftLeverPositionReq.Value
            IN_VeSR1B_y_ShiftLeverPositionReq_SigSts_Value: accessed-variable=VeSR1B_y_ShiftLeverPositionReq_SigSts.Value
        145 x sync call, all with timeout=1E-06:
          SC_FsftINVR_I_MtrA_DC_Crnt_FsftINVR_I_MtrA_DC_Crnt: operation=FsftINVR_I_MtrA_DC_Crnt.FsftINVR_I_MtrA_DC_Crnt, variation-point={short-label=vpSC_FsftINVR_I_MtrA_DC_Crnt_FsftINVR_I_MtrA_DC_Crnt, sw-syscond=1}
          SC_FsftINVR_I_MtrB_DC_Crnt_FsftINVR_I_MtrB_DC_Crnt: operation=FsftINVR_I_MtrB_DC_Crnt.FsftINVR_I_MtrB_DC_Crnt
          SC_FsftINVR_T_GPIMDCBusBarTemp_FsftINVR_T_GPIMDCBusBarTemp: operation=FsftINVR_T_GPIMDCBusBarTemp.FsftINVR_T_GPIMDCBusBarTemp, variation-point={short-label=vpSC_FsftINVR_T_GPIMDCBusBarTemp_FsftINVR_T_GPIMDCBusBarTemp, sw-syscond=1}
          SC_FsftINVR_T_MtrA_CtrlBoard_Temp_FsftINVR_T_MtrA_CtrlBoard_Temp: operation=FsftINVR_T_MtrA_CtrlBoard_Temp.FsftINVR_T_MtrA_CtrlBoard_Temp, variation-point={short-label=vpSC_FsftINVR_T_MtrA_CtrlBoard_Temp_FsftINVR_T_MtrA_CtrlBoard_Temp, sw-syscond=1}
          SC_FsftINVR_T_MtrA_InvrtrTemp_FsftINVR_T_MtrA_InvrtrTemp: operation=FsftINVR_T_MtrA_InvrtrTemp.FsftINVR_T_MtrA_InvrtrTemp, variation-point={short-label=vpSC_FsftINVR_T_MtrA_InvrtrTemp_FsftINVR_T_MtrA_InvrtrTemp, sw-syscond=1}
          SC_FsftINVR_T_MtrA_RotrTemp_FsftINVR_T_MtrA_RotrTemp: operation=FsftINVR_T_MtrA_RotrTemp.FsftINVR_T_MtrA_RotrTemp, variation-point={short-label=vpSC_FsftINVR_T_MtrA_RotrTemp_FsftINVR_T_MtrA_RotrTemp, sw-syscond=1}
          SC_FsftINVR_T_MtrA_Temp_FsftINVR_T_MtrA_Temp: operation=FsftINVR_T_MtrA_Temp.FsftINVR_T_MtrA_Temp, variation-point={short-label=vpSC_FsftINVR_T_MtrA_Temp_FsftINVR_T_MtrA_Temp, sw-syscond=1}
          SC_FsftINVR_T_MtrBBusBarTemp_FsftINVR_T_MtrBBusBarTemp: operation=FsftINVR_T_MtrBBusBarTemp.FsftINVR_T_MtrBBusBarTemp
          SC_FsftINVR_T_MtrB_CtrlBoard_Temp_FsftINVR_T_MtrB_CtrlBoard_Temp: operation=FsftINVR_T_MtrB_CtrlBoard_Temp.FsftINVR_T_MtrB_CtrlBoard_Temp
          SC_FsftINVR_T_MtrB_InvrtrTemp_FsftINVR_T_MtrB_InvrtrTemp: operation=FsftINVR_T_MtrB_InvrtrTemp.FsftINVR_T_MtrB_InvrtrTemp
          SC_FsftINVR_T_MtrB_RotrTemp_FsftINVR_T_MtrB_RotrTemp: operation=FsftINVR_T_MtrB_RotrTemp.FsftINVR_T_MtrB_RotrTemp
          SC_FsftINVR_T_MtrB_Temp_FsftINVR_T_MtrB_Temp: operation=FsftINVR_T_MtrB_Temp.FsftINVR_T_MtrB_Temp
          SC_FsftINVR_U_MtrA_DC_Volt_FsftINVR_U_MtrA_DC_Volt: operation=FsftINVR_U_MtrA_DC_Volt.FsftINVR_U_MtrA_DC_Volt, variation-point={short-label=vpSC_FsftINVR_U_MtrA_DC_Volt_FsftINVR_U_MtrA_DC_Volt, sw-syscond=1}
          SC_FsftINVR_U_MtrB_DC_Volt_FsftINVR_U_MtrB_DC_Volt: operation=FsftINVR_U_MtrB_DC_Volt.FsftINVR_U_MtrB_DC_Volt
          SC_FsftINVR_b_MCPA_HVILSts_FsftINVR_b_MCPA_HVILSts: operation=FsftINVR_b_MCPA_HVILSts.FsftINVR_b_MCPA_HVILSts, variation-point={short-label=vpSC_FsftINVR_b_MCPA_HVILSts_FsftINVR_b_MCPA_HVILSts, sw-syscond=1}
          SC_FsftINVR_b_MCPB_HVILSts_FsftINVR_b_MCPB_HVILSts: operation=FsftINVR_b_MCPB_HVILSts.FsftINVR_b_MCPB_HVILSts
          SC_FsftINVR_b_MtrAFlt_HV_CntctrOpnRq_FsftINVR_b_MtrAFlt_HV_CntctrOpnRq: operation=FsftINVR_b_MtrAFlt_HV_CntctrOpnRq.FsftINVR_b_MtrAFlt_HV_CntctrOpnRq, variation-point={short-label=vpSC_FsftINVR_b_MtrAFlt_HV_CntctrOpnRq_FsftINVR_b_MtrAFlt_HV_CntctrOpnRq, sw-syscond=1}
          SC_FsftINVR_b_MtrBFlt_HV_CntctrOpnRq_FsftINVR_b_MtrBFlt_HV_CntctrOpnRq: operation=FsftINVR_b_MtrBFlt_HV_CntctrOpnRq.FsftINVR_b_MtrBFlt_HV_CntctrOpnRq
          SC_FsftINVR_e_MCPA_SPT_State_FsftINVR_e_MCPA_SPT_State: operation=FsftINVR_e_MCPA_SPT_State.FsftINVR_e_MCPA_SPT_State, variation-point={short-label=vpSC_FsftINVR_e_MCPA_SPT_State_FsftINVR_e_MCPA_SPT_State, sw-syscond=1}
          SC_FsftINVR_e_MCPB_SPT_State_FsftINVR_e_MCPB_SPT_State: operation=FsftINVR_e_MCPB_SPT_State.FsftINVR_e_MCPB_SPT_State
          SC_FsftINVR_e_MtrA_Dschrge_Stat_FsftINVR_e_MtrA_Dschrge_Stat: operation=FsftINVR_e_MtrA_Dschrge_Stat.FsftINVR_e_MtrA_Dschrge_Stat, variation-point={short-label=vpSC_FsftINVR_e_MtrA_Dschrge_Stat_FsftINVR_e_MtrA_Dschrge_Stat, sw-syscond=1}
          SC_FsftINVR_e_MtrA_InvrtrSt_FsftINVR_e_MtrA_InvrtrSt: operation=FsftINVR_e_MtrA_InvrtrSt.FsftINVR_e_MtrA_InvrtrSt, variation-point={short-label=vpSC_FsftINVR_e_MtrA_InvrtrSt_FsftINVR_e_MtrA_InvrtrSt, sw-syscond=1}
          SC_FsftINVR_e_MtrB_Dschrge_Stat_FsftINVR_e_MtrB_Dschrge_Stat: operation=FsftINVR_e_MtrB_Dschrge_Stat.FsftINVR_e_MtrB_Dschrge_Stat
          SC_FsftINVR_e_MtrB_InvrtrSt_FsftINVR_e_MtrB_InvrtrSt: operation=FsftINVR_e_MtrB_InvrtrSt.FsftINVR_e_MtrB_InvrtrSt
          SC_FsftMSPR_dn_MtrA_AccelRaw_FsftMSPR_dn_MtrA_AccelRaw: operation=FsftMSPR_dn_MtrA_AccelRaw.FsftMSPR_dn_MtrA_AccelRaw, variation-point={short-label=vpSC_FsftMSPR_dn_MtrA_AccelRaw_FsftMSPR_dn_MtrA_AccelRaw, sw-syscond=1}
          SC_FsftMSPR_dn_MtrB_AccelRaw_FsftMSPR_dn_MtrB_AccelRaw: operation=FsftMSPR_dn_MtrB_AccelRaw.FsftMSPR_dn_MtrB_AccelRaw
          SC_FsftMSPR_n_MaxP1SpdLmt_FsftMSPR_n_MaxP1SpdLmt: operation=FsftMSPR_n_MaxP1SpdLmt.FsftMSPR_n_MaxP1SpdLmt, variation-point={short-label=vpSC_FsftMSPR_n_MaxP1SpdLmt_FsftMSPR_n_MaxP1SpdLmt, sw-syscond=1}
          SC_FsftMSPR_n_MaxP2SpdLmt_FsftMSPR_n_MaxP2SpdLmt: operation=FsftMSPR_n_MaxP2SpdLmt.FsftMSPR_n_MaxP2SpdLmt
          SC_FsftMSPR_n_MtrA_SpdRaw_FsftMSPR_n_MtrA_SpdRaw: operation=FsftMSPR_n_MtrA_SpdRaw.FsftMSPR_n_MtrA_SpdRaw, variation-point={short-label=vpSC_FsftMSPR_n_MtrA_SpdRaw_FsftMSPR_n_MtrA_SpdRaw, sw-syscond=1}
          SC_FsftMSPR_n_MtrB_SpdRaw_FsftMSPR_n_MtrB_SpdRaw: operation=FsftMSPR_n_MtrB_SpdRaw.FsftMSPR_n_MtrB_SpdRaw
          SC_FsftMTIR_M_MtrACapabilityMax_FsftMTIR_M_MtrACapabilityMax: operation=FsftMTIR_M_MtrACapabilityMax.FsftMTIR_M_MtrACapabilityMax, variation-point={short-label=vpSC_FsftMTIR_M_MtrACapabilityMax_FsftMTIR_M_MtrACapabilityMax, sw-syscond=1}
          SC_FsftMTIR_M_MtrACapabilityMin_FsftMTIR_M_MtrACapabilityMin: operation=FsftMTIR_M_MtrACapabilityMin.FsftMTIR_M_MtrACapabilityMin, variation-point={short-label=vpSC_FsftMTIR_M_MtrACapabilityMin_FsftMTIR_M_MtrACapabilityMin, sw-syscond=1}
          SC_FsftMTIR_M_MtrA_MaxTorq_FsftMTIR_M_MtrA_MaxTorq: operation=FsftMTIR_M_MtrA_MaxTorq.FsftMTIR_M_MtrA_MaxTorq, variation-point={short-label=vpSC_FsftMTIR_M_MtrA_MaxTorq_FsftMTIR_M_MtrA_MaxTorq, sw-syscond=1}
          SC_FsftMTIR_M_MtrA_MinTorq_FsftMTIR_M_MtrA_MinTorq: operation=FsftMTIR_M_MtrA_MinTorq.FsftMTIR_M_MtrA_MinTorq, variation-point={short-label=vpSC_FsftMTIR_M_MtrA_MinTorq_FsftMTIR_M_MtrA_MinTorq, sw-syscond=1}
          SC_FsftMTIR_M_MtrA_TorqAchieved_FsftMTIR_M_MtrA_TorqAchieved: operation=FsftMTIR_M_MtrA_TorqAchieved.FsftMTIR_M_MtrA_TorqAchieved, variation-point={short-label=vpSC_FsftMTIR_M_MtrA_TorqAchieved_FsftMTIR_M_MtrA_TorqAchieved, sw-syscond=1}
          SC_FsftMTIR_M_MtrA_TorqAchieved_AEMD_FsftMTIR_M_MtrA_TorqAchieved_AEMD: operation=FsftMTIR_M_MtrA_TorqAchieved_AEMD.FsftMTIR_M_MtrA_TorqAchieved_AEMD, variation-point={short-label=vpSC_FsftMTIR_M_MtrA_TorqAchieved_AEMD_FsftMTIR_M_MtrA_TorqAchieved_AEMD, sw-syscond=1}
          SC_FsftMTIR_M_MtrBCapabilityMax_FsftMTIR_M_MtrBCapabilityMax: operation=FsftMTIR_M_MtrBCapabilityMax.FsftMTIR_M_MtrBCapabilityMax
          SC_FsftMTIR_M_MtrBCapabilityMin_FsftMTIR_M_MtrBCapabilityMin: operation=FsftMTIR_M_MtrBCapabilityMin.FsftMTIR_M_MtrBCapabilityMin
          SC_FsftMTIR_M_MtrB_MaxTorq_FsftMTIR_M_MtrB_MaxTorq: operation=FsftMTIR_M_MtrB_MaxTorq.FsftMTIR_M_MtrB_MaxTorq
          SC_FsftMTIR_M_MtrB_MinTorq_FsftMTIR_M_MtrB_MinTorq: operation=FsftMTIR_M_MtrB_MinTorq.FsftMTIR_M_MtrB_MinTorq
          SC_FsftMTIR_M_MtrB_TorqAchieved_FsftMTIR_M_MtrB_TorqAchieved: operation=FsftMTIR_M_MtrB_TorqAchieved.FsftMTIR_M_MtrB_TorqAchieved
          SC_FsftMTIR_M_MtrB_TorqAchieved_AEMD_FsftMTIR_M_MtrB_TorqAchieved_AEMD: operation=FsftMTIR_M_MtrB_TorqAchieved_AEMD.FsftMTIR_M_MtrB_TorqAchieved_AEMD
          SC_FsftMTIR_k_MtrADeratingFactor_FsftMTIR_k_MtrADeratingFactor: operation=FsftMTIR_k_MtrADeratingFactor.FsftMTIR_k_MtrADeratingFactor, variation-point={short-label=vpSC_FsftMTIR_k_MtrADeratingFactor_FsftMTIR_k_MtrADeratingFactor, sw-syscond=1}
          SC_FsftMTIR_k_MtrBDeratingFactor_FsftMTIR_k_MtrBDeratingFactor: operation=FsftMTIR_k_MtrBDeratingFactor.FsftMTIR_k_MtrBDeratingFactor
          SC_FsftMTIR_n_MtrACapabilitySpd_FsftMTIR_n_MtrACapabilitySpd: operation=FsftMTIR_n_MtrACapabilitySpd.FsftMTIR_n_MtrACapabilitySpd, variation-point={short-label=vpSC_FsftMTIR_n_MtrACapabilitySpd_FsftMTIR_n_MtrACapabilitySpd, sw-syscond=1}
          SC_FsftMTIR_n_MtrBCapabilitySpd_FsftMTIR_n_MtrBCapabilitySpd: operation=FsftMTIR_n_MtrBCapabilitySpd.FsftMTIR_n_MtrBCapabilitySpd
          SC_FsftPLTR_b_Scndry_AutoPosCorrMd_FsftPLTR_b_Scndry_AutoPosCorrMd: operation=FsftPLTR_b_Scndry_AutoPosCorrMd.FsftPLTR_b_Scndry_AutoPosCorrMd
          SC_FsftPLTR_b_Scndry_ShiftSnsFA_FsftPLTR_b_Scndry_ShiftSnsFA: operation=FsftPLTR_b_Scndry_ShiftSnsFA.FsftPLTR_b_Scndry_ShiftSnsFA
          SC_FsftPLTR_b_Scndry_ShifterDispFA_FsftPLTR_b_Scndry_ShifterDispFA: operation=FsftPLTR_b_Scndry_ShifterDispFA.FsftPLTR_b_Scndry_ShifterDispFA
          SC_FsftPLTR_b_Scndry_TransShiftPstn_FsftPLTR_b_Scndry_TransShiftPstn: operation=FsftPLTR_b_Scndry_TransShiftPstn.FsftPLTR_b_Scndry_TransShiftPstn
          SC_FsftPPCR_b_Prmry_MPR_Pos_Sensor_FsftPPCR_b_Prmry_MPR_Pos_Sensor: operation=FsftPPCR_b_Prmry_MPR_Pos_Sensor.FsftPPCR_b_Prmry_MPR_Pos_Sensor
          SC_FsftPPCR_b_Prmry_PP_Motor_Pos_Stat_FsftPPCR_b_Prmry_PP_Motor_Pos_Stat: operation=FsftPPCR_b_Prmry_PP_Motor_Pos_Stat.FsftPPCR_b_Prmry_PP_Motor_Pos_Stat
          SC_FsftPPCR_b_Prmry_PP_Pos_Sensor_FsftPPCR_b_Prmry_PP_Pos_Sensor: operation=FsftPPCR_b_Prmry_PP_Pos_Sensor.FsftPPCR_b_Prmry_PP_Pos_Sensor
          SC_FsftPPCR_b_Prmry_Park_Pawl_Stat_FsftPPCR_b_Prmry_Park_Pawl_Stat: operation=FsftPPCR_b_Prmry_Park_Pawl_Stat.FsftPPCR_b_Prmry_Park_Pawl_Stat
          SC_FsftPPCR_b_Prmry_Park_Pawl_flt_Stat_FsftPPCR_b_Prmry_Park_Pawl_flt_Stat: operation=FsftPPCR_b_Prmry_Park_Pawl_flt_Stat.FsftPPCR_b_Prmry_Park_Pawl_flt_Stat
          SC_PokeHMIR_b_MCPA_Service_Lamp_Request_PokeHMIR_b_MCPA_Service_Lamp_Request: operation=PokeHMIR_b_MCPA_Service_Lamp_Request.PokeHMIR_b_MCPA_Service_Lamp_Request, variation-point={short-label=vpSC_PokeHMIR_b_MCPA_Service_Lamp_Request_PokeHMIR_b_MCPA_Service_Lamp_Request, sw-syscond=1}
          SC_PokeHMIR_b_MCPB_Service_Lamp_Request_PokeHMIR_b_MCPB_Service_Lamp_Request: operation=PokeHMIR_b_MCPB_Service_Lamp_Request.PokeHMIR_b_MCPB_Service_Lamp_Request
          SC_PokeINVR_I_MtrA_DC_Crnt_PokeINVR_I_MtrA_DC_Crnt: operation=PokeINVR_I_MtrA_DC_Crnt.PokeINVR_I_MtrA_DC_Crnt, variation-point={short-label=vpSC_PokeINVR_I_MtrA_DC_Crnt_PokeINVR_I_MtrA_DC_Crnt, sw-syscond=1}
          SC_PokeINVR_I_MtrB_DC_Crnt_PokeINVR_I_MtrB_DC_Crnt: operation=PokeINVR_I_MtrB_DC_Crnt.PokeINVR_I_MtrB_DC_Crnt
          SC_PokeINVR_T_GPIMDCBusBarTemp_PokeINVR_T_GPIMDCBusBarTemp: operation=PokeINVR_T_GPIMDCBusBarTemp.PokeINVR_T_GPIMDCBusBarTemp, variation-point={short-label=vpSC_PokeINVR_T_GPIMDCBusBarTemp_PokeINVR_T_GPIMDCBusBarTemp, sw-syscond=1}
          SC_PokeINVR_T_MtrA_CtrlBoard_Temp_PokeINVR_T_MtrA_CtrlBoard_Temp: operation=PokeINVR_T_MtrA_CtrlBoard_Temp.PokeINVR_T_MtrA_CtrlBoard_Temp, variation-point={short-label=vpSC_PokeINVR_T_MtrA_CtrlBoard_Temp_PokeINVR_T_MtrA_CtrlBoard_Temp, sw-syscond=1}
          SC_PokeINVR_T_MtrA_InvrtrTemp_PokeINVR_T_MtrA_InvrtrTemp: operation=PokeINVR_T_MtrA_InvrtrTemp.PokeINVR_T_MtrA_InvrtrTemp, variation-point={short-label=vpSC_PokeINVR_T_MtrA_InvrtrTemp_PokeINVR_T_MtrA_InvrtrTemp, sw-syscond=1}
          SC_PokeINVR_T_MtrA_RotrTemp_PokeINVR_T_MtrA_RotrTemp: operation=PokeINVR_T_MtrA_RotrTemp.PokeINVR_T_MtrA_RotrTemp, variation-point={short-label=vpSC_PokeINVR_T_MtrA_RotrTemp_PokeINVR_T_MtrA_RotrTemp, sw-syscond=1}
          SC_PokeINVR_T_MtrA_Temp_PokeINVR_T_MtrA_Temp: operation=PokeINVR_T_MtrA_Temp.PokeINVR_T_MtrA_Temp, variation-point={short-label=vpSC_PokeINVR_T_MtrA_Temp_PokeINVR_T_MtrA_Temp, sw-syscond=1}
          SC_PokeINVR_T_MtrBBusBarTemp_PokeINVR_T_MtrBBusBarTemp: operation=PokeINVR_T_MtrBBusBarTemp.PokeINVR_T_MtrBBusBarTemp
          SC_PokeINVR_T_MtrB_CtrlBoard_Temp_PokeINVR_T_MtrB_CtrlBoard_Temp: operation=PokeINVR_T_MtrB_CtrlBoard_Temp.PokeINVR_T_MtrB_CtrlBoard_Temp
          SC_PokeINVR_T_MtrB_InvrtrTemp_PokeINVR_T_MtrB_InvrtrTemp: operation=PokeINVR_T_MtrB_InvrtrTemp.PokeINVR_T_MtrB_InvrtrTemp
          SC_PokeINVR_T_MtrB_RotrTemp_PokeINVR_T_MtrB_RotrTemp: operation=PokeINVR_T_MtrB_RotrTemp.PokeINVR_T_MtrB_RotrTemp
          SC_PokeINVR_T_MtrB_Temp_PokeINVR_T_MtrB_Temp: operation=PokeINVR_T_MtrB_Temp.PokeINVR_T_MtrB_Temp
          SC_PokeINVR_U_MtrA_DC_Volt_PokeINVR_U_MtrA_DC_Volt: operation=PokeINVR_U_MtrA_DC_Volt.PokeINVR_U_MtrA_DC_Volt, variation-point={short-label=vpSC_PokeINVR_U_MtrA_DC_Volt_PokeINVR_U_MtrA_DC_Volt, sw-syscond=1}
          SC_PokeINVR_U_MtrB_DC_Volt_PokeINVR_U_MtrB_DC_Volt: operation=PokeINVR_U_MtrB_DC_Volt.PokeINVR_U_MtrB_DC_Volt
          SC_PokeINVR_b_MtrAFlt_HV_CntctrOpnRq_PokeINVR_b_MtrAFlt_HV_CntctrOpnRq: operation=PokeINVR_b_MtrAFlt_HV_CntctrOpnRq.PokeINVR_b_MtrAFlt_HV_CntctrOpnRq, variation-point={short-label=vpSC_PokeINVR_b_MtrAFlt_HV_CntctrOpnRq_PokeINVR_b_MtrAFlt_HV_CntctrOpnRq, sw-syscond=1}
          SC_PokeINVR_b_MtrA_SpdRawFA_PokeINVR_b_MtrA_SpdRawFA: operation=PokeINVR_b_MtrA_SpdRawFA.PokeINVR_b_MtrA_SpdRawFA, variation-point={short-label=vpSC_PokeINVR_b_MtrA_SpdRawFA_PokeINVR_b_MtrA_SpdRawFA, sw-syscond=1}
          SC_PokeINVR_b_MtrA_TorqAchievedFA_PokeINVR_b_MtrA_TorqAchievedFA: operation=PokeINVR_b_MtrA_TorqAchievedFA.PokeINVR_b_MtrA_TorqAchievedFA, variation-point={short-label=vpSC_PokeINVR_b_MtrA_TorqAchievedFA_PokeINVR_b_MtrA_TorqAchievedFA, sw-syscond=1}
          SC_PokeINVR_b_MtrBFlt_HV_CntctrOpnRq_PokeINVR_b_MtrBFlt_HV_CntctrOpnRq: operation=PokeINVR_b_MtrBFlt_HV_CntctrOpnRq.PokeINVR_b_MtrBFlt_HV_CntctrOpnRq
          SC_PokeINVR_e_MCPA_HVILSts_PokeINVR_e_MCPA_HVILSts: operation=PokeINVR_e_MCPA_HVILSts.PokeINVR_e_MCPA_HVILSts, variation-point={short-label=vpSC_PokeINVR_e_MCPA_HVILSts_PokeINVR_e_MCPA_HVILSts, sw-syscond=1}
          SC_PokeINVR_e_MCPA_SPT_State_PokeINVR_e_MCPA_SPT_State: operation=PokeINVR_e_MCPA_SPT_State.PokeINVR_e_MCPA_SPT_State, variation-point={short-label=vpSC_PokeINVR_e_MCPA_SPT_State_PokeINVR_e_MCPA_SPT_State, sw-syscond=1}
          SC_PokeINVR_e_MCPB_HVILSts_PokeINVR_e_MCPB_HVILSts: operation=PokeINVR_e_MCPB_HVILSts.PokeINVR_e_MCPB_HVILSts
          SC_PokeINVR_e_MCPB_SPT_State_PokeINVR_e_MCPB_SPT_State: operation=PokeINVR_e_MCPB_SPT_State.PokeINVR_e_MCPB_SPT_State
          SC_PokeINVR_e_MtrA_6SOEnbl_PokeINVR_e_MtrA_6SOEnbl: operation=PokeINVR_e_MtrA_6SOEnbl.PokeINVR_e_MtrA_6SOEnbl, variation-point={short-label=vpSC_PokeINVR_e_MtrA_6SOEnbl_PokeINVR_e_MtrA_6SOEnbl, sw-syscond=1}
          SC_PokeINVR_e_MtrA_DrtRsn_PokeINVR_e_MtrA_DrtRsn: operation=PokeINVR_e_MtrA_DrtRsn.PokeINVR_e_MtrA_DrtRsn, variation-point={short-label=vpSC_PokeINVR_e_MtrA_DrtRsn_PokeINVR_e_MtrA_DrtRsn, sw-syscond=1}
          SC_PokeINVR_e_MtrA_Dschrge_Stat_PokeINVR_e_MtrA_Dschrge_Stat: operation=PokeINVR_e_MtrA_Dschrge_Stat.PokeINVR_e_MtrA_Dschrge_Stat, variation-point={short-label=vpSC_PokeINVR_e_MtrA_Dschrge_Stat_PokeINVR_e_MtrA_Dschrge_Stat, sw-syscond=1}
          SC_PokeINVR_e_MtrA_InvrtrSt_PokeINVR_e_MtrA_InvrtrSt: operation=PokeINVR_e_MtrA_InvrtrSt.PokeINVR_e_MtrA_InvrtrSt, variation-point={short-label=vpSC_PokeINVR_e_MtrA_InvrtrSt_PokeINVR_e_MtrA_InvrtrSt, sw-syscond=1}
          SC_PokeINVR_e_MtrB_6SOEnbl_PokeINVR_e_MtrB_6SOEnbl: operation=PokeINVR_e_MtrB_6SOEnbl.PokeINVR_e_MtrB_6SOEnbl
          SC_PokeINVR_e_MtrB_DrtRsn_PokeINVR_e_MtrB_DrtRsn: operation=PokeINVR_e_MtrB_DrtRsn.PokeINVR_e_MtrB_DrtRsn
          SC_PokeINVR_e_MtrB_Dschrge_Stat_PokeINVR_e_MtrB_Dschrge_Stat: operation=PokeINVR_e_MtrB_Dschrge_Stat.PokeINVR_e_MtrB_Dschrge_Stat
          SC_PokeINVR_e_MtrB_InvrtrSt_PokeINVR_e_MtrB_InvrtrSt: operation=PokeINVR_e_MtrB_InvrtrSt.PokeINVR_e_MtrB_InvrtrSt
          SC_PokeMSPR_dn_MtrA_AccelRaw_PokeMSPR_dn_MtrA_AccelRaw: operation=PokeMSPR_dn_MtrA_AccelRaw.PokeMSPR_dn_MtrA_AccelRaw, variation-point={short-label=vpSC_PokeMSPR_dn_MtrA_AccelRaw_PokeMSPR_dn_MtrA_AccelRaw, sw-syscond=1}
          SC_PokeMSPR_dn_MtrB_AccelRaw_PokeMSPR_dn_MtrB_AccelRaw: operation=PokeMSPR_dn_MtrB_AccelRaw.PokeMSPR_dn_MtrB_AccelRaw
          SC_PokeMSPR_n_MaxP1SpdLmt_PokeMSPR_n_MaxP1SpdLmt: operation=PokeMSPR_n_MaxP1SpdLmt.PokeMSPR_n_MaxP1SpdLmt, variation-point={short-label=vpSC_PokeMSPR_n_MaxP1SpdLmt_PokeMSPR_n_MaxP1SpdLmt, sw-syscond=1}
          SC_PokeMSPR_n_MaxP2SpdLmt_PokeMSPR_n_MaxP2SpdLmt: operation=PokeMSPR_n_MaxP2SpdLmt.PokeMSPR_n_MaxP2SpdLmt
          SC_PokeMSPR_n_MtrA_SpdRaw_PokeMSPR_n_MtrA_SpdRaw: operation=PokeMSPR_n_MtrA_SpdRaw.PokeMSPR_n_MtrA_SpdRaw, variation-point={short-label=vpSC_PokeMSPR_n_MtrA_SpdRaw_PokeMSPR_n_MtrA_SpdRaw, sw-syscond=1}
          SC_PokeMSPR_n_MtrB_SpdRaw_PokeMSPR_n_MtrB_SpdRaw: operation=PokeMSPR_n_MtrB_SpdRaw.PokeMSPR_n_MtrB_SpdRaw
          SC_PokeMTIR_M_MtrACapabilityMax_PokeMTIR_M_MtrACapabilityMax: operation=PokeMTIR_M_MtrACapabilityMax.PokeMTIR_M_MtrACapabilityMax, variation-point={short-label=vpSC_PokeMTIR_M_MtrACapabilityMax_PokeMTIR_M_MtrACapabilityMax, sw-syscond=1}
          SC_PokeMTIR_M_MtrACapabilityMin_PokeMTIR_M_MtrACapabilityMin: operation=PokeMTIR_M_MtrACapabilityMin.PokeMTIR_M_MtrACapabilityMin, variation-point={short-label=vpSC_PokeMTIR_M_MtrACapabilityMin_PokeMTIR_M_MtrACapabilityMin, sw-syscond=1}
          SC_PokeMTIR_M_MtrA_MaxTorq_PokeMTIR_M_MtrA_MaxTorq: operation=PokeMTIR_M_MtrA_MaxTorq.PokeMTIR_M_MtrA_MaxTorq, variation-point={short-label=vpSC_PokeMTIR_M_MtrA_MaxTorq_PokeMTIR_M_MtrA_MaxTorq, sw-syscond=1}
          SC_PokeMTIR_M_MtrA_MinTorq_PokeMTIR_M_MtrA_MinTorq: operation=PokeMTIR_M_MtrA_MinTorq.PokeMTIR_M_MtrA_MinTorq, variation-point={short-label=vpSC_PokeMTIR_M_MtrA_MinTorq_PokeMTIR_M_MtrA_MinTorq, sw-syscond=1}
          SC_PokeMTIR_M_MtrA_TorqAchieved_PokeMTIR_M_MtrA_TorqAchieved: operation=PokeMTIR_M_MtrA_TorqAchieved.PokeMTIR_M_MtrA_TorqAchieved, variation-point={short-label=vpSC_PokeMTIR_M_MtrA_TorqAchieved_PokeMTIR_M_MtrA_TorqAchieved, sw-syscond=1}
          SC_PokeMTIR_M_MtrA_TorqAchieved_AEMD_PokeMTIR_M_MtrA_TorqAchieved_AEMD: operation=PokeMTIR_M_MtrA_TorqAchieved_AEMD.PokeMTIR_M_MtrA_TorqAchieved_AEMD, variation-point={short-label=vpSC_PokeMTIR_M_MtrA_TorqAchieved_AEMD_PokeMTIR_M_MtrA_TorqAchieved_AEMD, sw-syscond=1}
          SC_PokeMTIR_M_MtrBCapabilityMax_PokeMTIR_M_MtrBCapabilityMax: operation=PokeMTIR_M_MtrBCapabilityMax.PokeMTIR_M_MtrBCapabilityMax
          SC_PokeMTIR_M_MtrBCapabilityMin_PokeMTIR_M_MtrBCapabilityMin: operation=PokeMTIR_M_MtrBCapabilityMin.PokeMTIR_M_MtrBCapabilityMin
          SC_PokeMTIR_M_MtrB_MaxTorq_PokeMTIR_M_MtrB_MaxTorq: operation=PokeMTIR_M_MtrB_MaxTorq.PokeMTIR_M_MtrB_MaxTorq
          SC_PokeMTIR_M_MtrB_MinTorq_PokeMTIR_M_MtrB_MinTorq: operation=PokeMTIR_M_MtrB_MinTorq.PokeMTIR_M_MtrB_MinTorq
          SC_PokeMTIR_M_MtrB_TorqAchieved_PokeMTIR_M_MtrB_TorqAchieved: operation=PokeMTIR_M_MtrB_TorqAchieved.PokeMTIR_M_MtrB_TorqAchieved
          SC_PokeMTIR_M_MtrB_TorqAchieved_AEMD_PokeMTIR_M_MtrB_TorqAchieved_AEMD: operation=PokeMTIR_M_MtrB_TorqAchieved_AEMD.PokeMTIR_M_MtrB_TorqAchieved_AEMD
          SC_PokeMTIR_k_MtrADeratingFactor_PokeMTIR_k_MtrADeratingFactor: operation=PokeMTIR_k_MtrADeratingFactor.PokeMTIR_k_MtrADeratingFactor, variation-point={short-label=vpSC_PokeMTIR_k_MtrADeratingFactor_PokeMTIR_k_MtrADeratingFactor, sw-syscond=1}
          SC_PokeMTIR_k_MtrBDeratingFactor_PokeMTIR_k_MtrBDeratingFactor: operation=PokeMTIR_k_MtrBDeratingFactor.PokeMTIR_k_MtrBDeratingFactor
          SC_PokeMTIR_n_MtrACapabilitySpd_PokeMTIR_n_MtrACapabilitySpd: operation=PokeMTIR_n_MtrACapabilitySpd.PokeMTIR_n_MtrACapabilitySpd, variation-point={short-label=vpSC_PokeMTIR_n_MtrACapabilitySpd_PokeMTIR_n_MtrACapabilitySpd, sw-syscond=1}
          SC_PokeMTIR_n_MtrBCapabilitySpd_PokeMTIR_n_MtrBCapabilitySpd: operation=PokeMTIR_n_MtrBCapabilitySpd.PokeMTIR_n_MtrBCapabilitySpd
          SC_PokePLTR_b_Scndry_ShiftSnsFA_PokePLTR_b_Scndry_ShiftSnsFA: operation=PokePLTR_b_Scndry_ShiftSnsFA.PokePLTR_b_Scndry_ShiftSnsFA
          SC_PokePLTR_b_Scndry_ShifterDispFA_PokePLTR_b_Scndry_ShifterDispFA: operation=PokePLTR_b_Scndry_ShifterDispFA.PokePLTR_b_Scndry_ShifterDispFA
          SC_PokePLTR_e_Scndry_AutoPosCorrMd_PokePLTR_e_Scndry_AutoPosCorrMd: operation=PokePLTR_e_Scndry_AutoPosCorrMd.PokePLTR_e_Scndry_AutoPosCorrMd
          SC_PokePLTR_e_Scndry_TransShiftPstn_PokePLTR_e_Scndry_TransShiftPstn: operation=PokePLTR_e_Scndry_TransShiftPstn.PokePLTR_e_Scndry_TransShiftPstn
          SC_PokePPCR_e_Prmry_MPR_Pos_Sensor_PokePPCR_e_Prmry_MPR_Pos_Sensor: operation=PokePPCR_e_Prmry_MPR_Pos_Sensor.PokePPCR_e_Prmry_MPR_Pos_Sensor
          SC_PokePPCR_e_Prmry_PP_Motor_Pos_Stat_PokePPCR_e_Prmry_PP_Motor_Pos_Stat: operation=PokePPCR_e_Prmry_PP_Motor_Pos_Stat.PokePPCR_e_Prmry_PP_Motor_Pos_Stat
          SC_PokePPCR_e_Prmry_PP_Pos_Sensor_PokePPCR_e_Prmry_PP_Pos_Sensor: operation=PokePPCR_e_Prmry_PP_Pos_Sensor.PokePPCR_e_Prmry_PP_Pos_Sensor
          SC_PokePPCR_e_Prmry_Park_Pawl_Stat_PokePPCR_e_Prmry_Park_Pawl_Stat: operation=PokePPCR_e_Prmry_Park_Pawl_Stat.PokePPCR_e_Prmry_Park_Pawl_Stat
          SC_PokePPCR_e_Prmry_Park_Pawl_flt_Stat_PokePPCR_e_Prmry_Park_Pawl_flt_Stat: operation=PokePPCR_e_Prmry_Park_Pawl_flt_Stat.PokePPCR_e_Prmry_Park_Pawl_flt_Stat
          SC_TmotINVR_b_MCPA_SPT_State_TmotINVR_b_MCPA_SPT_State: operation=TmotINVR_b_MCPA_SPT_State.TmotINVR_b_MCPA_SPT_State, variation-point={short-label=vpSC_TmotINVR_b_MCPA_SPT_State_TmotINVR_b_MCPA_SPT_State, sw-syscond=1}
          SC_TmotINVR_b_MCPB_SPT_State_TmotINVR_b_MCPB_SPT_State: operation=TmotINVR_b_MCPB_SPT_State.TmotINVR_b_MCPB_SPT_State
          SC_TmotINVR_b_MtrA_6SOEnbl_TmotINVR_b_MtrA_6SOEnbl: operation=TmotINVR_b_MtrA_6SOEnbl.TmotINVR_b_MtrA_6SOEnbl, variation-point={short-label=vpSC_TmotINVR_b_MtrA_6SOEnbl_TmotINVR_b_MtrA_6SOEnbl, sw-syscond=1}
          SC_TmotINVR_b_MtrA_CtrlBoard_Temp_TmotINVR_b_MtrA_CtrlBoard_Temp: operation=TmotINVR_b_MtrA_CtrlBoard_Temp.TmotINVR_b_MtrA_CtrlBoard_Temp, variation-point={short-label=vpSC_TmotINVR_b_MtrA_CtrlBoard_Temp_TmotINVR_b_MtrA_CtrlBoard_Temp, sw-syscond=1}
          SC_TmotINVR_b_MtrA_DC_Crnt_TmotINVR_b_MtrA_DC_Crnt: operation=TmotINVR_b_MtrA_DC_Crnt.TmotINVR_b_MtrA_DC_Crnt, variation-point={short-label=vpSC_TmotINVR_b_MtrA_DC_Crnt_TmotINVR_b_MtrA_DC_Crnt, sw-syscond=1}
          SC_TmotINVR_b_MtrA_DC_Volt_TmotINVR_b_MtrA_DC_Volt: operation=TmotINVR_b_MtrA_DC_Volt.TmotINVR_b_MtrA_DC_Volt, variation-point={short-label=vpSC_TmotINVR_b_MtrA_DC_Volt_TmotINVR_b_MtrA_DC_Volt, sw-syscond=1}
          SC_TmotINVR_b_MtrA_InvrtrSt_TmotINVR_b_MtrA_InvrtrSt: operation=TmotINVR_b_MtrA_InvrtrSt.TmotINVR_b_MtrA_InvrtrSt, variation-point={short-label=vpSC_TmotINVR_b_MtrA_InvrtrSt_TmotINVR_b_MtrA_InvrtrSt, sw-syscond=1}
          SC_TmotINVR_b_MtrA_InvrtrTemp_TmotINVR_b_MtrA_InvrtrTemp: operation=TmotINVR_b_MtrA_InvrtrTemp.TmotINVR_b_MtrA_InvrtrTemp, variation-point={short-label=vpSC_TmotINVR_b_MtrA_InvrtrTemp_TmotINVR_b_MtrA_InvrtrTemp, sw-syscond=1}
          SC_TmotINVR_b_MtrA_RotrTemp_TmotINVR_b_MtrA_RotrTemp: operation=TmotINVR_b_MtrA_RotrTemp.TmotINVR_b_MtrA_RotrTemp, variation-point={short-label=vpSC_TmotINVR_b_MtrA_RotrTemp_TmotINVR_b_MtrA_RotrTemp, sw-syscond=1}
          SC_TmotINVR_b_MtrA_Temp_TmotINVR_b_MtrA_Temp: operation=TmotINVR_b_MtrA_Temp.TmotINVR_b_MtrA_Temp, variation-point={short-label=vpSC_TmotINVR_b_MtrA_Temp_TmotINVR_b_MtrA_Temp, sw-syscond=1}
          SC_TmotINVR_b_MtrBFlt_HV_CntctrOpnRq_TmotINVR_b_MtrBFlt_HV_CntctrOpnRq: operation=TmotINVR_b_MtrBFlt_HV_CntctrOpnRq.TmotINVR_b_MtrBFlt_HV_CntctrOpnRq
          SC_TmotINVR_b_MtrB_6SOEnbl_TmotINVR_b_MtrB_6SOEnbl: operation=TmotINVR_b_MtrB_6SOEnbl.TmotINVR_b_MtrB_6SOEnbl
          SC_TmotINVR_b_MtrB_CtrlBoard_Temp_TmotINVR_b_MtrB_CtrlBoard_Temp: operation=TmotINVR_b_MtrB_CtrlBoard_Temp.TmotINVR_b_MtrB_CtrlBoard_Temp
          SC_TmotINVR_b_MtrB_DC_Crnt_TmotINVR_b_MtrB_DC_Crnt: operation=TmotINVR_b_MtrB_DC_Crnt.TmotINVR_b_MtrB_DC_Crnt
          SC_TmotINVR_b_MtrB_DC_Volt_TmotINVR_b_MtrB_DC_Volt: operation=TmotINVR_b_MtrB_DC_Volt.TmotINVR_b_MtrB_DC_Volt
          SC_TmotINVR_b_MtrB_InvrtrSt_TmotINVR_b_MtrB_InvrtrSt: operation=TmotINVR_b_MtrB_InvrtrSt.TmotINVR_b_MtrB_InvrtrSt
          SC_TmotINVR_b_MtrB_InvrtrTemp_TmotINVR_b_MtrB_InvrtrTemp: operation=TmotINVR_b_MtrB_InvrtrTemp.TmotINVR_b_MtrB_InvrtrTemp
          SC_TmotINVR_b_MtrB_RotrTemp_TmotINVR_b_MtrB_RotrTemp: operation=TmotINVR_b_MtrB_RotrTemp.TmotINVR_b_MtrB_RotrTemp
          SC_TmotINVR_b_MtrB_Temp_TmotINVR_b_MtrB_Temp: operation=TmotINVR_b_MtrB_Temp.TmotINVR_b_MtrB_Temp
          SC_TmotMSPR_b_MtrA_AccelRaw_TmotMSPR_b_MtrA_AccelRaw: operation=TmotMSPR_b_MtrA_AccelRaw.TmotMSPR_b_MtrA_AccelRaw, variation-point={short-label=vpSC_TmotMSPR_b_MtrA_AccelRaw_TmotMSPR_b_MtrA_AccelRaw, sw-syscond=1}
          SC_TmotMSPR_b_MtrA_SpdRaw_TmotMSPR_b_MtrA_SpdRaw: operation=TmotMSPR_b_MtrA_SpdRaw.TmotMSPR_b_MtrA_SpdRaw, variation-point={short-label=vpSC_TmotMSPR_b_MtrA_SpdRaw_TmotMSPR_b_MtrA_SpdRaw, sw-syscond=1}
          SC_TmotMSPR_b_MtrB_AccelRaw_TmotMSPR_b_MtrB_AccelRaw: operation=TmotMSPR_b_MtrB_AccelRaw.TmotMSPR_b_MtrB_AccelRaw
          SC_TmotMSPR_b_MtrB_SpdRaw_TmotMSPR_b_MtrB_SpdRaw: operation=TmotMSPR_b_MtrB_SpdRaw.TmotMSPR_b_MtrB_SpdRaw
          SC_TmotMSPR_n_MaxP1SpdLmt_TmotMSPR_n_MaxP1SpdLmt: operation=TmotMSPR_n_MaxP1SpdLmt.TmotMSPR_n_MaxP1SpdLmt, variation-point={short-label=vpSC_TmotMSPR_n_MaxP1SpdLmt_TmotMSPR_n_MaxP1SpdLmt, sw-syscond=1}
          SC_TmotMSPR_n_MaxP2SpdLmt_TmotMSPR_n_MaxP2SpdLmt: operation=TmotMSPR_n_MaxP2SpdLmt.TmotMSPR_n_MaxP2SpdLmt
          SC_TmotMTIR_b_MtrA_TorqAchieved_AEMD_TmotMTIR_b_MtrA_TorqAchieved_AEMD: operation=TmotMTIR_b_MtrA_TorqAchieved_AEMD.TmotMTIR_b_MtrA_TorqAchieved_AEMD, variation-point={short-label=vpSC_TmotMTIR_b_MtrA_TorqAchieved_AEMD_TmotMTIR_b_MtrA_TorqAchieved_AEMD, sw-syscond=1}
          SC_TmotMTIR_b_MtrB_TorqAchieved_AEMD_TmotMTIR_b_MtrB_TorqAchieved_AEMD: operation=TmotMTIR_b_MtrB_TorqAchieved_AEMD.TmotMTIR_b_MtrB_TorqAchieved_AEMD
      237 x variation point proxy, all with category=CONDITION:
        VrntCR4B_C1Status: condition-access=0
        VrntCR4B_CompressionTest: condition-access=0
        VrntCR4B_ECMLHOMTransW: condition-access=0
        VrntCR4B_ETRQMode: condition-access=0
        VrntCR4B_EngActStdyStTorq: condition-access=0
        VrntCR4B_EngActuatorsStat: condition-access=0
        VrntCR4B_EngAirFlwStdyStTorq: condition-access=0
        VrntCR4B_EngCltTmp: condition-access=0
        VrntCR4B_EngMinSparkNomCurrAirTorqCap: condition-access=0
        VrntCR4B_EngRunCrnkAct: condition-access=0
        VrntCR4B_EngTorqACCCapability: condition-access=0
        VrntCR4B_EngTorqCapbltyMaxOffTorq: condition-access=0
        VrntCR4B_EngTorqCapbltyMaxTorq: condition-access=0
        VrntCR4B_EngTorqCapbltyMinRunTorq: condition-access=0
        VrntCR4B_EngTorqCapbltyMinTorq: condition-access=0
        VrntCR4B_EngTorqCapbltyRefEngSpd: condition-access=0
        VrntCR4B_EngTrqEnblRqTCMW: condition-access=0
        VrntCR4B_EngTrqReserveReq: condition-access=0
        VrntCR4B_EngineSpeedW: condition-access=0
        VrntCR4B_EngineStallDetected: condition-access=0
        VrntCR4B_EssEngSt: condition-access=0
        VrntCR4B_EssEngStopIsNotAllwd: condition-access=0
        VrntCR4B_EssEngStopIsNotAllwdID: condition-access=0
        VrntCR4B_EssEngStrtIsNotAllwd: condition-access=0
        VrntCR4B_EssEngStrtIsNotAllwdID: condition-access=0
        VrntCR4B_FeedbackHCP: condition-access=0
        VrntCR4B_GasFlwEnblsFuAtStr: condition-access=0
        VrntCR4B_GearShiftType: condition-access=0
        VrntCR4B_HybActEngTorqRespTyp: condition-access=0
        VrntCR4B_LV12PwrFreeRqW: condition-access=0
        VrntCR4B_MAP4BARPHEV: condition-access=0
        VrntCR4B_MCPA3PSPosP: condition-access=0
        VrntCR4B_MCPA6SOStatusP: condition-access=1
        VrntCR4B_MCPA6SOStatusP_PokeINVRMtrA_6SOEnbl: condition-access=1
        VrntCR4B_MCPA6SOStatusP_PokeINVRMtrC_6SOEnbl: condition-access=0
        VrntCR4B_MCPA6SOStatusP_TmotINVRMtrA_6SOEnbl: condition-access=1
        VrntCR4B_MCPA6SOStatusP_TmotINVRMtrC_6SOEnbl: condition-access=0
        VrntCR4B_MCPAAccelRawP: condition-access=1
        VrntCR4B_MCPAAccelRawP_FsftMSPRMtrA_AccelRaw: condition-access=1
        VrntCR4B_MCPAAccelRawP_FsftMSPRMtrC_AccelRaw: condition-access=0
        VrntCR4B_MCPAAccelRawP_PokeMSPRMtrA_AccelRaw: condition-access=1
        VrntCR4B_MCPAAccelRawP_PokeMSPRMtrC_AccelRaw: condition-access=0
        VrntCR4B_MCPAAccelRawP_TmotMSPRMtrA_AccelRaw: condition-access=1
        VrntCR4B_MCPAAccelRawP_TmotMSPRMtrC_AccelRaw: condition-access=0
        VrntCR4B_MCPAControlBoardTemperatureP: condition-access=1
        VrntCR4B_MCPAControlBoardTemperatureP_FsftINVRMtrA_CtrlBoard_Te: condition-access=1
        VrntCR4B_MCPAControlBoardTemperatureP_FsftINVRMtrC_CtrlBoard_Te: condition-access=0
        VrntCR4B_MCPAControlBoardTemperatureP_PokeINVRMtrA_CtrlBoard_Te: condition-access=1
        VrntCR4B_MCPAControlBoardTemperatureP_PokeINVRMtrC_CtrlBoard_Te: condition-access=0
        VrntCR4B_MCPAControlBoardTemperatureP_TmotINVRMtrA_CtrlBoard_Te: condition-access=1
        VrntCR4B_MCPAControlBoardTemperatureP_TmotINVRMtrC_CtrlBoard_Te: condition-access=0
        VrntCR4B_MCPACpbltySpdDivVoltP: condition-access=1
        VrntCR4B_MCPACpbltySpdDivVoltP_FsftMTIRMtrACapabilitySpd: condition-access=1
        VrntCR4B_MCPACpbltySpdDivVoltP_FsftMTIRMtrCCapabilitySpd: condition-access=0
        VrntCR4B_MCPACpbltySpdDivVoltP_PokeMTIRMtrACapabilitySpd: condition-access=1
        VrntCR4B_MCPACpbltySpdDivVoltP_PokeMTIRMtrCCapabilitySpd: condition-access=0
        VrntCR4B_MCPADCCurrentP: condition-access=1
        VrntCR4B_MCPADCCurrentP_FsftINVRMtrA_DC_Crnt: condition-access=1
        VrntCR4B_MCPADCCurrentP_FsftINVRMtrC_DC_Crnt: condition-access=0
        VrntCR4B_MCPADCCurrentP_PokeINVRMtrA_DC_Crnt: condition-access=1
        VrntCR4B_MCPADCCurrentP_PokeINVRMtrC_DC_Crnt: condition-access=0
        VrntCR4B_MCPADCCurrentP_TmotINVRMtrA_DC_Crnt: condition-access=1
        VrntCR4B_MCPADCCurrentP_TmotINVRMtrC_DC_Crnt: condition-access=0
        VrntCR4B_MCPADCVoltageP: condition-access=1
        VrntCR4B_MCPADCVoltageP_FsftINVRMtrA_DC_Volt: condition-access=1
        VrntCR4B_MCPADCVoltageP_FsftINVRMtrC_DC_Volt: condition-access=0
        VrntCR4B_MCPADCVoltageP_PokeINVRMtrA_DC_Volt: condition-access=1
        VrntCR4B_MCPADCVoltageP_PokeINVRMtrC_DC_Volt: condition-access=0
        VrntCR4B_MCPADCVoltageP_TmotINVRMtrA_DC_Volt: condition-access=1
        VrntCR4B_MCPADCVoltageP_TmotINVRMtrC_DC_Volt: condition-access=0
        VrntCR4B_MCPADerateReasonP: condition-access=1
        VrntCR4B_MCPADerateReasonP_PokeINVRMtrA_DrtRsn: condition-access=1
        VrntCR4B_MCPADerateReasonP_PokeINVRMtrC_DrtRsn: condition-access=0
        VrntCR4B_MCPADeratingFactorP: condition-access=1
        VrntCR4B_MCPADeratingFactorP_FsftMTIRMtrADeratingFactor: condition-access=1
        VrntCR4B_MCPADeratingFactorP_FsftMTIRMtrCDeratingFactor: condition-access=0
        VrntCR4B_MCPADeratingFactorP_PokeMTIRMtrADeratingFactor: condition-access=1
        VrntCR4B_MCPADeratingFactorP_PokeMTIRMtrCDeratingFactor: condition-access=0
        VrntCR4B_MCPADschrgeStatusP: condition-access=1
        VrntCR4B_MCPADschrgeStatusP_FsftINVRMtrA_Dschrge_Stat: condition-access=1
        VrntCR4B_MCPADschrgeStatusP_FsftINVRMtrC_Dschrge_Stat: condition-access=0
        VrntCR4B_MCPADschrgeStatusP_PokeINVRMtrA_Dschrge_Stat: condition-access=1
        VrntCR4B_MCPADschrgeStatusP_PokeINVRMtrC_Dschrge_Stat: condition-access=0
        VrntCR4B_MCPAHVCnctrOpnReqP: condition-access=1
        VrntCR4B_MCPAHVCnctrOpnReqP_FsftINVRMtrAFlt_HV_CntctrOpnRq: condition-access=1
        VrntCR4B_MCPAHVCnctrOpnReqP_FsftINVRMtrCFlt_HV_CntctrOpnRq: condition-access=0
        VrntCR4B_MCPAHVCnctrOpnReqP_PokeINVRMtrAFlt_HV_CntctrOpnRq: condition-access=1
        VrntCR4B_MCPAHVCnctrOpnReqP_PokeINVRMtrCFlt_HV_CntctrOpnRq: condition-access=0
        VrntCR4B_MCPAInterlockStsP: condition-access=1
        VrntCR4B_MCPAInterlockStsP_FsftINVRMCPA_HVILSts: condition-access=1
        VrntCR4B_MCPAInterlockStsP_FsftINVRMCPC_HVILSts: condition-access=0
        VrntCR4B_MCPAInterlockStsP_PokeINVRMCPA_HVILSts: condition-access=1
        VrntCR4B_MCPAInterlockStsP_PokeINVRMCPC_HVILSts: condition-access=0
        VrntCR4B_MCPAInverterTempP: condition-access=1
        VrntCR4B_MCPAInverterTempP_FsftINVRMtrA_InvrtrTemp: condition-access=1
        VrntCR4B_MCPAInverterTempP_FsftINVRMtrC_InvrtrTemp: condition-access=0
        VrntCR4B_MCPAInverterTempP_PokeINVRMtrA_InvrtrTemp: condition-access=1
        VrntCR4B_MCPAInverterTempP_PokeINVRMtrC_InvrtrTemp: condition-access=0
        VrntCR4B_MCPAInverterTempP_TmotINVRMtrA_InvrtrTemp: condition-access=1
        VrntCR4B_MCPAInverterTempP_TmotINVRMtrC_InvrtrTemp: condition-access=0
        VrntCR4B_MCPAInvrtrStateP: condition-access=1
        VrntCR4B_MCPAInvrtrStateP_FsftINVRMtrA_InvrtrSt: condition-access=1
        VrntCR4B_MCPAInvrtrStateP_FsftINVRMtrC_InvrtrSt: condition-access=0
        VrntCR4B_MCPAInvrtrStateP_PokeINVRMtrA_InvrtrSt: condition-access=1
        VrntCR4B_MCPAInvrtrStateP_PokeINVRMtrC_InvrtrSt: condition-access=0
        VrntCR4B_MCPAInvrtrStateP_TmotINVRMtrA_InvrtrSt: condition-access=1
        VrntCR4B_MCPAInvrtrStateP_TmotINVRMtrC_InvrtrSt: condition-access=0
        VrntCR4B_MCPAMaxTorqP: condition-access=1
        VrntCR4B_MCPAMaxTorqP_FsftMTIRMtrA_MaxTorq: condition-access=1
        VrntCR4B_MCPAMaxTorqP_FsftMTIRMtrC_MaxTorq: condition-access=0
        VrntCR4B_MCPAMaxTorqP_PokeMTIRMtrA_MaxTorq: condition-access=1
        VrntCR4B_MCPAMaxTorqP_PokeMTIRMtrC_MaxTorq: condition-access=0
        VrntCR4B_MCPAMinTorqP: condition-access=1
        VrntCR4B_MCPAMinTorqP_FsftMTIRMtrA_MinTorq: condition-access=1
        VrntCR4B_MCPAMinTorqP_FsftMTIRMtrC_MinTorq: condition-access=0
        VrntCR4B_MCPAMinTorqP_PokeMTIRMtrA_MinTorq: condition-access=1
        VrntCR4B_MCPAMinTorqP_PokeMTIRMtrC_MinTorq: condition-access=0
        VrntCR4B_MCPAMtrMaxCpbltyTrqP: condition-access=1
        VrntCR4B_MCPAMtrMaxCpbltyTrqP_FsftMTIRMtrACapabilityMax: condition-access=1
        VrntCR4B_MCPAMtrMaxCpbltyTrqP_FsftMTIRMtrCCapabilityMax: condition-access=0
        VrntCR4B_MCPAMtrMaxCpbltyTrqP_PokeMTIRMtrACapabilityMax: condition-access=1
        VrntCR4B_MCPAMtrMaxCpbltyTrqP_PokeMTIRMtrCCapabilityMax: condition-access=0
        VrntCR4B_MCPAMtrMinCpbltyTrqP: condition-access=1
        VrntCR4B_MCPAMtrMinCpbltyTrqP_FsftMTIRMtrACapabilityMin: condition-access=1
        VrntCR4B_MCPAMtrMinCpbltyTrqP_FsftMTIRMtrCCapabilityMin: condition-access=0
        VrntCR4B_MCPAMtrMinCpbltyTrqP_PokeMTIRMtrACapabilityMin: condition-access=1
        VrntCR4B_MCPAMtrMinCpbltyTrqP_PokeMTIRMtrCCapabilityMin: condition-access=0
        VrntCR4B_MCPAPIMDCSideBusbarTempP: condition-access=1
        VrntCR4B_MCPAPIMDCSideBusbarTempP_FsftINVRGPIMDCBusBarTemp: condition-access=1
        VrntCR4B_MCPAPIMDCSideBusbarTempP_FsftINVRMtrCBusBarTemp: condition-access=0
        VrntCR4B_MCPAPIMDCSideBusbarTempP_PokeINVRGPIMDCBusBarTemp: condition-access=1
        VrntCR4B_MCPAPIMDCSideBusbarTempP_PokeINVRMtrCBusBarTemp: condition-access=0
        VrntCR4B_MCPARPMP: condition-access=1
        VrntCR4B_MCPARPMP_FsftMSPRMtrA_SpdRaw: condition-access=1
        VrntCR4B_MCPARPMP_FsftMSPRMtrC_SpdRaw: condition-access=0
        VrntCR4B_MCPARPMP_PokeMSPRMtrA_SpdRaw: condition-access=1
        VrntCR4B_MCPARPMP_PokeMSPRMtrC_SpdRaw: condition-access=0
        VrntCR4B_MCPARPMP_TmotMSPRMtrA_SpdRaw: condition-access=1
        VrntCR4B_MCPARPMP_TmotMSPRMtrC_SpdRaw: condition-access=0
        VrntCR4B_MCPARPMVP: condition-access=1
        VrntCR4B_MCPARotorTemperatureP: condition-access=1
        VrntCR4B_MCPARotorTemperatureP_FsftINVRMtrA_RotrTemp: condition-access=1
        VrntCR4B_MCPARotorTemperatureP_FsftINVRMtrC_RotrTemp: condition-access=0
        VrntCR4B_MCPARotorTemperatureP_PokeINVRMtrA_RotrTemp: condition-access=1
        VrntCR4B_MCPARotorTemperatureP_PokeINVRMtrC_RotrTemp: condition-access=0
        VrntCR4B_MCPARotorTemperatureP_TmotINVRMtrA_RotrTemp: condition-access=1
        VrntCR4B_MCPARotorTemperatureP_TmotINVRMtrC_RotrTemp: condition-access=0
        VrntCR4B_MCPASPTStatP: condition-access=1
        VrntCR4B_MCPASPTStatP_FsftINVRMCPA_SPT_State: condition-access=1
        VrntCR4B_MCPASPTStatP_FsftINVRMCPC_SPT_State: condition-access=0
        VrntCR4B_MCPASPTStatP_PokeINVRMCPA_SPT_State: condition-access=1
        VrntCR4B_MCPASPTStatP_PokeINVRMCPC_SPT_State: condition-access=0
        VrntCR4B_MCPASPTStatP_TmotINVRMCPA_SPT_State: condition-access=1
        VrntCR4B_MCPASPTStatP_TmotINVRMCPC_SPT_State: condition-access=0
        VrntCR4B_MCPAServiceLampRequestP: condition-access=1
        VrntCR4B_MCPAServiceLampRequestP_PokeHMIRMCPA_Service_Lamp_Requ: condition-access=1
        VrntCR4B_MCPAServiceLampRequestP_PokeHMIRMCPC_Service_Lamp_Requ: condition-access=0
        VrntCR4B_MCPASpdLimP: condition-access=1
        VrntCR4B_MCPASpdLimP_FsftMSPRMaxMtrCSpdLmt: condition-access=0
        VrntCR4B_MCPASpdLimP_FsftMSPRMaxP1SpdLmt: condition-access=1
        VrntCR4B_MCPASpdLimP_PokeMSPRMaxMtrCSpdLmt: condition-access=0
        VrntCR4B_MCPASpdLimP_PokeMSPRMaxP1SpdLmt: condition-access=1
        VrntCR4B_MCPASpdLimP_TmotMSPRMaxMtrCSpdLmt: condition-access=0
        VrntCR4B_MCPASpdLimP_TmotMSPRMaxP1SpdLmt: condition-access=1
        VrntCR4B_MCPATempP: condition-access=1
        VrntCR4B_MCPATempP_FsftINVRMtrA_Temp: condition-access=1
        VrntCR4B_MCPATempP_FsftINVRMtrC_Temp: condition-access=0
        VrntCR4B_MCPATempP_PokeINVRMtrA_Temp: condition-access=1
        VrntCR4B_MCPATempP_PokeINVRMtrC_Temp: condition-access=0
        VrntCR4B_MCPATempP_TmotINVRMtrA_Temp: condition-access=1
        VrntCR4B_MCPATempP_TmotINVRMtrC_Temp: condition-access=0
        VrntCR4B_MCPATorqAchievedAEMDP: condition-access=1
        VrntCR4B_MCPATorqAchievedAEMDP_FsftMTIRMtrA_TorqAchieved_AEMD: condition-access=1
        VrntCR4B_MCPATorqAchievedAEMDP_FsftMTIRMtrC_TorqAchieved_AEMD: condition-access=0
        VrntCR4B_MCPATorqAchievedAEMDP_PokeMTIRMtrA_TorqAchieved_AEMD: condition-access=1
        VrntCR4B_MCPATorqAchievedAEMDP_PokeMTIRMtrC_TorqAchieved_AEMD: condition-access=0
        VrntCR4B_MCPATorqAchievedAEMDP_TmotMTIRMtrA_TorqAchieved_AEMD: condition-access=1
        VrntCR4B_MCPATorqAchievedAEMDP_TmotMTIRMtrC_TorqAchieved_AEMD: condition-access=0
        VrntCR4B_MCPATorqueAchievedP: condition-access=1
        VrntCR4B_MCPATorqueAchievedP_FsftMTIRMtrA_TorqAchieved: condition-access=1
        VrntCR4B_MCPATorqueAchievedP_FsftMTIRMtrC_TorqAchieved: condition-access=0
        VrntCR4B_MCPATorqueAchievedP_PokeMTIRMtrA_TorqAchieved: condition-access=1
        VrntCR4B_MCPATorqueAchievedP_PokeMTIRMtrC_TorqAchieved: condition-access=0
        VrntCR4B_MCPATorqueAchievedVP: condition-access=1
        VrntCR4B_MRGBCurrentGr: condition-access=0
        VrntCR4B_MRGBMaxGrAllwd: condition-access=0
        VrntCR4B_MRGBMaxTrqDes: condition-access=0
        VrntCR4B_MRGBMinGrAllwd: condition-access=0
        VrntCR4B_MRGBMtrBTrqRq: condition-access=0
        VrntCR4B_MRGBOutputSpeed: condition-access=0
        VrntCR4B_MRGBTargetGr: condition-access=0
        VrntCR4B_MRGBTransmOilTemp: condition-access=0
        VrntCR4B_MRGBTrqCtrlModeReq: condition-access=0
        VrntCR4B_MRGBUpshiftTime: condition-access=0
        VrntCR4B_MaxEngSpdCap: condition-access=0
        VrntCR4B_MaxOffEngTorqCap: condition-access=0
        VrntCR4B_MaxPrdtdEngTorqCap: condition-access=0
        VrntCR4B_MinAirFlowMinSparkTorqCap: condition-access=0
        VrntCR4B_MinEngPowerReqForOilDil: condition-access=0
        VrntCR4B_MinEngPowerReqForOilDilEnabler: condition-access=0
        VrntCR4B_MinEngSpdCap: condition-access=0
        VrntCR4B_MinEngTorqCap: condition-access=0
        VrntCR4B_MinImmedEngTorqCap: condition-access=0
        VrntCR4B_MinPrdtdEngRunTorqCap: condition-access=0
        VrntCR4B_RedSpkAuthorityAvbl: condition-access=0
        VrntCR4B_SGCP6SOStatusP: condition-access=0
        VrntCR4B_SGCPAccelRawP: condition-access=0
        VrntCR4B_SGCPControlBoardTemperatureP: condition-access=0
        VrntCR4B_SGCPCpbltySpdDivVoltP: condition-access=0
        VrntCR4B_SGCPDCCurrentP: condition-access=0
        VrntCR4B_SGCPDCVoltageP: condition-access=0
        VrntCR4B_SGCPDerateReasonP: condition-access=0
        VrntCR4B_SGCPDeratingFactorP: condition-access=0
        VrntCR4B_SGCPDschrgeStatusP: condition-access=0
        VrntCR4B_SGCPHVCnctrOpnReqP: condition-access=0
        VrntCR4B_SGCPInterlockStsP: condition-access=0
        VrntCR4B_SGCPInverterTempP: condition-access=0
        VrntCR4B_SGCPInvrtrStateP: condition-access=0
        VrntCR4B_SGCPMaxTorqP: condition-access=0
        VrntCR4B_SGCPMinTorqP: condition-access=0
        VrntCR4B_SGCPMtrMaxCpbltyTrqP: condition-access=0
        VrntCR4B_SGCPMtrMinCpbltyTrqP: condition-access=0
        VrntCR4B_SGCPPIMACSideBusbarTempP: condition-access=0
        VrntCR4B_SGCPPIMDCSideBusbarTempP: condition-access=0
        VrntCR4B_SGCPRPMP: condition-access=0
        VrntCR4B_SGCPRPMVP: condition-access=0
        VrntCR4B_SGCPRotorTemperatureP: condition-access=0
        VrntCR4B_SGCPSPTStatP: condition-access=0
        VrntCR4B_SGCPServiceLampRequestP: condition-access=0
        VrntCR4B_SGCPSpdLimP: condition-access=0
        VrntCR4B_SGCPTempP: condition-access=0
        VrntCR4B_SGCPTorqAchievedAEMDP: condition-access=0
        VrntCR4B_SGCPTorqueAchievedP: condition-access=0
        VrntCR4B_SGCPTorqueAchievedVP: condition-access=0
        VrntCR4B_ServiceHybSys: condition-access=0
        VrntCR4B_TCapActualC2: condition-access=0
        VrntCR4B_TransTrqRatio: condition-access=0
